VERSION "..\..\trunk\components\winTestMT\code\canApi\dbcFiles\canBus_10.dbc, created by Octave and generateRandomDbc.m on 21-Feb-2017"

NS_ :

BS_:

BU_: ECU

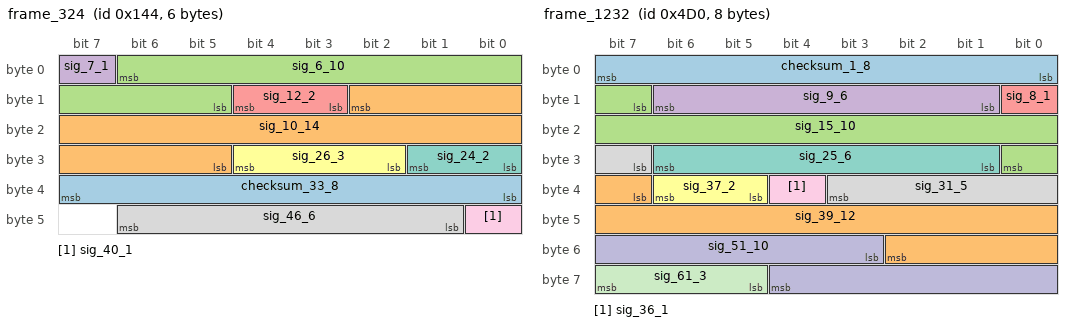
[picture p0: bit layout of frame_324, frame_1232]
BO_ 324 frame_324: 6 Vector__XXX
  SG_ checksum_33_8 : 32|8@1+ (1.0,0.0) [0.0|255.0] "" ECU
  SG_ sig_10_14 : 10|14@0+ (1.0000000000000009E-9,3.162277660168379E-6) [3.162277660168379E-6|1.954427766016839E-5] "km/h" ECU
  SG_ sig_6_10 : 6|10@0- (1.0,0.0) [-512.0|510.0] "" ECU
  SG_ sig_7_1 : 7|1@0+ (1.0,0.0) [0.0|1.0] "" ECU
  SG_ sig_12_2 : 12|2@0+ (1.0,0.0) [0.0|3.0] "" ECU
  SG_ sig_26_3 : 26|3@1+ (1.0,0.0) [0.0|6.0] "" ECU
  SG_ sig_24_2 : 24|2@1+ (1.0,0.0) [0.0|3.0] "" ECU
  SG_ sig_46_6 : 46|6@0+ (1.0000000000000006E-6,0.0) [0.0|6.200000000000004E-5] "kWh" ECU
  SG_ sig_40_1 : 40|1@1+ (1.0,0.0) [0.0|1.0] "" ECU

BO_ 1232 frame_1232: 8 Vector__XXX
  SG_ checksum_1_8 : 0|8@1+ (1.0,0.0) [0.0|255.0] "" ECU
  SG_ sig_39_12 : 39|12@1+ (1.0000000000000008E-8,-3.1622776601683795E-5) [-3.1622776601683795E-5|9.317223398316236E-6] "m/s^2" ECU
  SG_ sig_15_10 : 15|10@1+ (0.010000000000000002,3.1622776601683795) [3.1622776601683795|13.382277660168382] "V" ECU
  SG_ sig_9_6 : 9|6@1- (1.0000000000000005E-4,-0.0031622776601683794) [-0.006362277660168381|-1.6227766016837803E-4] "W" ECU
  SG_ sig_8_1 : 8|1@1+ (1.0,0.0) [0.0|1.0] "" ECU
  SG_ sig_37_2 : 37|2@1+ (1.0,0.0) [0.0|3.0] "" ECU
  SG_ sig_25_6 : 25|6@1- (1000.0,0.0) [-32000.0|30000.0] "s" ECU
  SG_ sig_31_5 : 31|5@1+ (1000.0,-31622.776601683792) [-31622.776601683792|-1622.7766016837923] "V" ECU
  SG_ sig_36_1 : 36|1@1+ (1.0,0.0) [0.0|1.0] "" ECU
  SG_ sig_51_10 : 51|10@1- (0.0010000000000000002,0.31622776601683794) [-0.19577223398316218|0.826227766016838] "A" ECU
  SG_ sig_61_3 : 61|3@1+ (1.0,0.0) [0.0|6.0] "" ECU

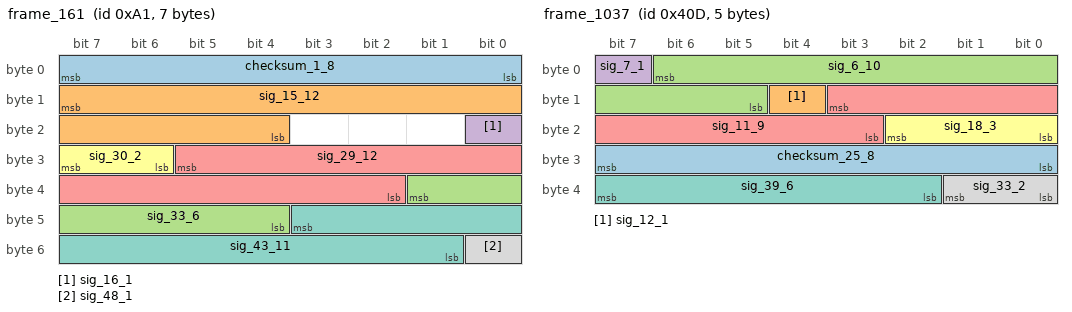
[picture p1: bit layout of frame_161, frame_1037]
BO_ 161 frame_161: 7 Vector__XXX
  SG_ checksum_1_8 : 0|8@1+ (1.0,0.0) [0.0|255.0] "" ECU
  SG_ sig_15_12 : 15|12@0- (0.010000000000000002,-31.622776601683793) [-52.1027766016838|-11.162776601683788] "km/h" ECU
  SG_ sig_33_6 : 33|6@0+ (0.1,0.0) [0.0|6.2] "km/h" ECU
  SG_ sig_16_1 : 16|1@1+ (1.0,0.0) [0.0|1.0] "" ECU
  SG_ sig_29_12 : 29|12@0- (1.0,0.0) [-2048.0|2046.0] "" ECU
  SG_ sig_30_2 : 30|2@1+ (1.0,0.0) [0.0|3.0] "" ECU
  SG_ sig_43_11 : 43|11@0+ (1.0000000000000008E-8,0.0) [0.0|2.0460000000000018E-5] "kWh" ECU
  SG_ sig_48_1 : 48|1@0+ (1.0,0.0) [0.0|1.0] "" ECU

BO_ 1037 frame_1037: 5 Vector__XXX
  SG_ checksum_25_8 : 31|8@0+ (1.0,0.0) [0.0|255.0] "" ECU
  SG_ sig_12_1 : 12|1@0+ (1.0,0.0) [0.0|1.0] "" ECU
  SG_ sig_6_10 : 6|10@0- (1.0,0.0) [-512.0|510.0] "" ECU
  SG_ sig_7_1 : 7|1@0+ (1.0,0.0) [0.0|1.0] "" ECU
  SG_ sig_11_9 : 11|9@0- (0.0010000000000000002,0.31622776601683794) [0.06022776601683788|0.570227766016838] "kWh" ECU
  SG_ sig_18_3 : 18|3@0- (1.0,0.0) [-4.0|2.0] "" ECU
  SG_ sig_39_6 : 39|6@0- (1.0,0.0) [-32.0|30.0] "" ECU
  SG_ sig_33_2 : 33|2@0- (1.0,0.0) [-2.0|1.0] "" ECU

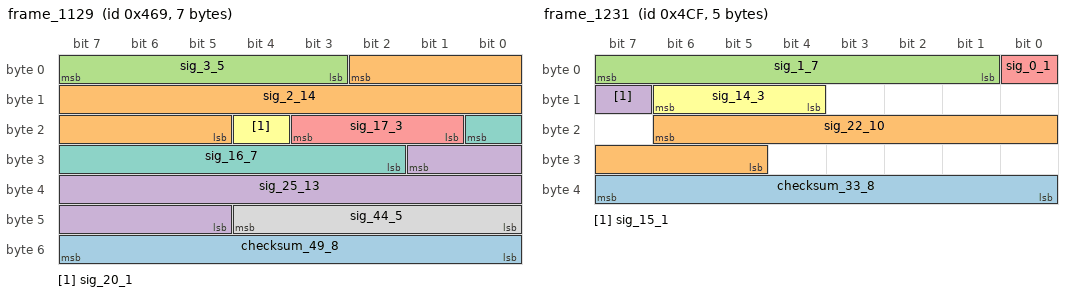
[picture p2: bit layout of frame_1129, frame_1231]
BO_ 1129 frame_1129: 7 Vector__XXX
  SG_ checksum_49_8 : 48|8@1+ (1.0,0.0) [0.0|255.0] "" ECU
  SG_ sig_2_14 : 2|14@0- (1.0000000000000009E-9,0.0) [-8.192000000000007E-6|8.190000000000008E-6] "kWh" ECU
  SG_ sig_3_5 : 3|5@1+ (1.0,0.0) [0.0|30.0] "" ECU
  SG_ sig_25_13 : 25|13@0+ (1.0,0.0) [0.0|8190.0] "" ECU
  SG_ sig_17_3 : 17|3@1+ (1.0,0.0) [0.0|6.0] "" ECU
  SG_ sig_20_1 : 20|1@0+ (1.0,0.0) [0.0|1.0] "" ECU
  SG_ sig_16_7 : 16|7@0- (1000.0,31622.776601683792) [-32377.223398316208|93622.77660168378] "s" ECU
  SG_ sig_44_5 : 44|5@0+ (1.0000000000000005E-4,0.0) [0.0|0.0030000000000000014] "V" ECU

BO_ 1231 frame_1231: 5 Vector__XXX
  SG_ checksum_33_8 : 32|8@1+ (1.0,0.0) [0.0|255.0] "" ECU
  SG_ sig_22_10 : 22|10@0+ (1.0000000000000007E-7,-3.1622776601683795E-5) [-3.1622776601683795E-5|7.057722339831628E-5] "s" ECU
  SG_ sig_1_7 : 1|7@1+ (100.0,3162.2776601683795) [3162.2776601683795|15762.27766016838] "A" ECU
  SG_ sig_15_1 : 15|1@0+ (1.0,0.0) [0.0|1.0] "" ECU
  SG_ sig_0_1 : 0|1@1+ (1.0,0.0) [0.0|1.0] "" ECU
  SG_ sig_14_3 : 14|3@0- (1.0,0.0) [-4.0|2.0] "" ECU

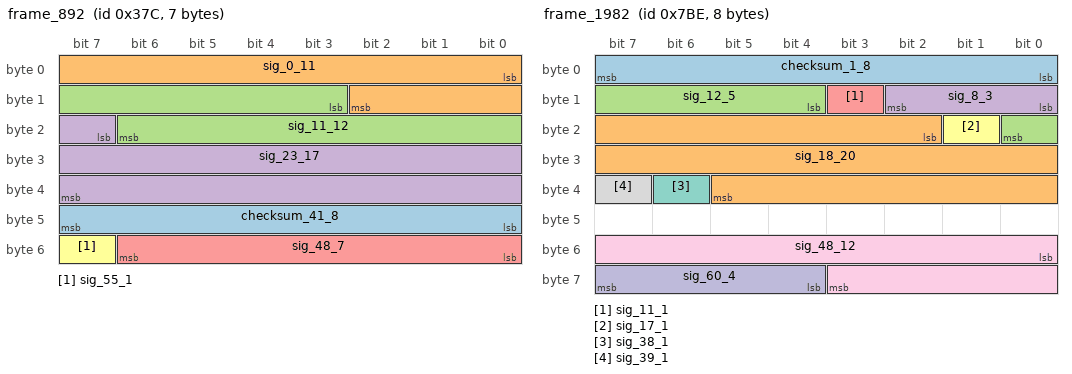
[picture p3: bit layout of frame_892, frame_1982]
BO_ 892 frame_892: 7 Vector__XXX
  SG_ checksum_41_8 : 40|8@1+ (1.0,0.0) [0.0|255.0] "" ECU
  SG_ sig_0_11 : 0|11@1- (0.1,-31.622776601683793) [-134.0227766016838|70.5772233983162] "s" ECU
  SG_ sig_11_12 : 11|12@1+ (1.0000000000000005E-4,0.0) [0.0|0.4094000000000002] "W" ECU
  SG_ sig_23_17 : 23|17@1- (0.1,-3162.2776601683795) [-9715.87766016838|3391.122339831621] "A" ECU
  SG_ sig_48_7 : 48|7@1+ (1.0000000000000006E-6,3.1622776601683795E-5) [3.1622776601683795E-5|1.5762277660168387E-4] "V" ECU
  SG_ sig_55_1 : 55|1@1+ (1.0,0.0) [0.0|1.0] "" ECU

BO_ 612 frame_612: 5 ECU
  SG_ checksum_1_8 : 7|8@0+ (1.0,0.0) [0.0|255.0] "" Vector__XXX
  SG_ sig_16_16 : 16|16@0- (1.0000000000000005E-4,3.1622776601683795) [-0.11452233983162197|6.438877660168381] "m/s^2" Vector__XXX
  SG_ sig_15_9 : 15|9@0+ (1.0000000000000007E-7,-3.1622776601683795E-5) [-3.1622776601683795E-5|1.9377223398316245E-5] "kWh" Vector__XXX
  SG_ sig_22_6 : 22|6@0+ (0.0010000000000000002,-0.03162277660168379) [-0.03162277660168379|0.030377223398316222] "A" Vector__XXX

BO_ 1982 frame_1982: 8 Vector__XXX
  SG_ checksum_1_8 : 0|8@1+ (1.0,0.0) [0.0|255.0] "" ECU
  SG_ sig_18_20 : 18|20@1+ (1.000000000000001E-11,3.162277660168379E-6) [3.162277660168379E-6|1.364801766016839E-5] "A" ECU
  SG_ sig_12_5 : 12|5@1+ (1.0000000000000007E-7,0.0) [0.0|3.000000000000002E-6] "kWh" ECU
  SG_ sig_8_3 : 8|3@1+ (1.0,0.0) [0.0|6.0] "" ECU
  SG_ sig_11_1 : 11|1@1+ (1.0,0.0) [0.0|1.0] "" ECU
  SG_ sig_17_1 : 17|1@1+ (1.0,0.0) [0.0|1.0] "" ECU
  SG_ sig_38_1 : 38|1@1+ (1.0,0.0) [0.0|1.0] "" ECU
  SG_ sig_39_1 : 39|1@1+ (1.0,0.0) [0.0|1.0] "" ECU
  SG_ sig_48_12 : 48|12@1- (1.0000000000000007E-7,0.0) [-2.0480000000000015E-4|2.0460000000000015E-4] "kWh" ECU
  SG_ sig_60_4 : 60|4@1- (10000.0,-31622.776601683792) [-111622.77660168378|28377.223398316208] "A" ECU

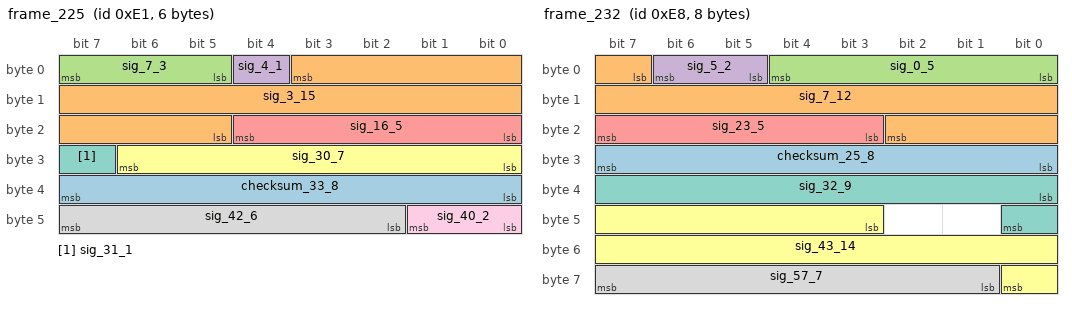
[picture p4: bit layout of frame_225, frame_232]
BO_ 225 frame_225: 6 Vector__XXX
  SG_ checksum_33_8 : 32|8@1+ (1.0,0.0) [0.0|255.0] "" ECU
  SG_ sig_3_15 : 3|15@0- (1.0,0.0) [-16384.0|16382.0] "" ECU
  SG_ sig_7_3 : 7|3@0- (1.0,0.0) [-4.0|2.0] "" ECU
  SG_ sig_4_1 : 4|1@0+ (1.0,0.0) [0.0|1.0] "" ECU
  SG_ sig_16_5 : 16|5@1+ (1.0000000000000006E-6,3.1622776601683795E-5) [3.1622776601683795E-5|6.162277660168381E-5] "m/s^2" ECU
  SG_ sig_30_7 : 30|7@0- (1.0,0.0) [-64.0|62.0] "" ECU
  SG_ sig_31_1 : 31|1@1+ (1.0,0.0) [0.0|1.0] "" ECU
  SG_ sig_42_6 : 42|6@1- (0.1,-3.1622776601683795) [-6.362277660168379|-0.16227766016837952] "kWh" ECU
  SG_ sig_40_2 : 40|2@1+ (1.0,0.0) [0.0|3.0] "" ECU

BO_ 5 frame_5: 4 ECU
  SG_ checksum_17_8 : 23|8@0+ (1.0,0.0) [0.0|255.0] "" Vector__XXX
  SG_ sig_0_13 : 0|13@1- (1.0000000000000009E-9,0.0) [-4.096000000000004E-6|4.0940000000000035E-6] "s" Vector__XXX
  SG_ sig_31_8 : 31|8@0+ (1.0,0.0) [0.0|254.0] "" Vector__XXX

BO_ 232 frame_232: 8 Vector__XXX
  SG_ checksum_25_8 : 31|8@0+ (1.0,0.0) [0.0|255.0] "" ECU
  SG_ sig_7_12 : 7|12@1+ (1.0000000000000009E-9,0.0) [0.0|4.0940000000000035E-6] "A" ECU
  SG_ sig_0_5 : 0|5@1- (1.0000000000000006E-6,0.0) [-1.600000000000001E-5|1.4000000000000008E-5] "kWh" ECU
  SG_ sig_5_2 : 5|2@1+ (1.0,0.0) [0.0|3.0] "" ECU
  SG_ sig_23_5 : 23|5@0- (1.0,0.0) [-16.0|14.0] "" ECU
  SG_ sig_43_14 : 43|14@1- (1.0000000000000006E-5,0.03162277660168379) [-0.05029722339831626|0.11352277660168383] "km/h" ECU
  SG_ sig_32_9 : 32|9@1+ (100.0,0.0) [0.0|51000.0] "s" ECU
  SG_ sig_57_7 : 57|7@1+ (1000.0,31622.776601683792) [31622.776601683792|157622.77660168378] "W" ECU

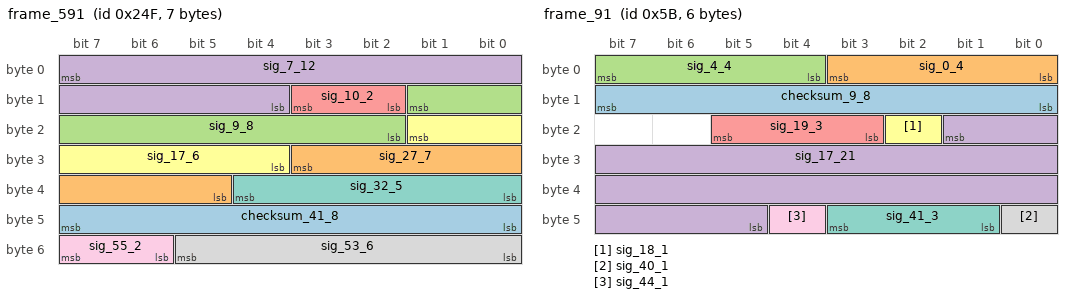
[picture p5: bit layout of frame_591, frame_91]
BO_ 591 frame_591: 7 Vector__XXX
  SG_ checksum_41_8 : 40|8@1+ (1.0,0.0) [0.0|255.0] "" ECU
  SG_ sig_27_7 : 27|7@0+ (0.0010000000000000002,0.03162277660168379) [0.03162277660168379|0.15762277660168383] "km/h" ECU
  SG_ sig_9_8 : 9|8@0+ (100.0,3162.2776601683795) [3162.2776601683795|28562.27766016838] "kWh" ECU
  SG_ sig_7_12 : 7|12@0- (1.0000000000000009E-9,3.162277660168379E-6) [1.1142776601683774E-6|5.208277660168381E-6] "A" ECU
  SG_ sig_10_2 : 10|2@1+ (1.0,0.0) [0.0|3.0] "" ECU
  SG_ sig_17_6 : 17|6@0+ (10.0,-316.22776601683796) [-316.22776601683796|303.77223398316204] "A" ECU
  SG_ sig_32_5 : 32|5@1- (1000.0,0.0) [-16000.0|14000.0] "A" ECU
  SG_ sig_53_6 : 53|6@0- (1.0,0.0) [-32.0|30.0] "" ECU
  SG_ sig_55_2 : 55|2@0- (1.0,0.0) [-2.0|1.0] "" ECU

BO_ 91 frame_91: 6 Vector__XXX
  SG_ checksum_9_8 : 8|8@1+ (1.0,0.0) [0.0|255.0] "" ECU
  SG_ sig_0_4 : 0|4@1- (1.0000000000000005E-4,-3.1622776601683794E-4) [-0.0011162277660168383|2.8377223398316233E-4] "V" ECU
  SG_ sig_4_4 : 4|4@1- (1.0,0.0) [-8.0|6.0] "" ECU
  SG_ sig_17_21 : 17|21@0+ (1.000000000000001E-11,-3.162277660168379E-6) [-3.162277660168379E-6|1.7809222339831644E-5] "kWh" ECU
  SG_ sig_19_3 : 19|3@1- (1.0,0.0) [-4.0|2.0] "" ECU
  SG_ sig_18_1 : 18|1@1+ (1.0,0.0) [0.0|1.0] "" ECU
  SG_ sig_41_3 : 41|3@1+ (1.0,0.0) [0.0|6.0] "" ECU
  SG_ sig_40_1 : 40|1@1+ (1.0,0.0) [0.0|1.0] "" ECU
  SG_ sig_44_1 : 44|1@1+ (1.0,0.0) [0.0|1.0] "" ECU

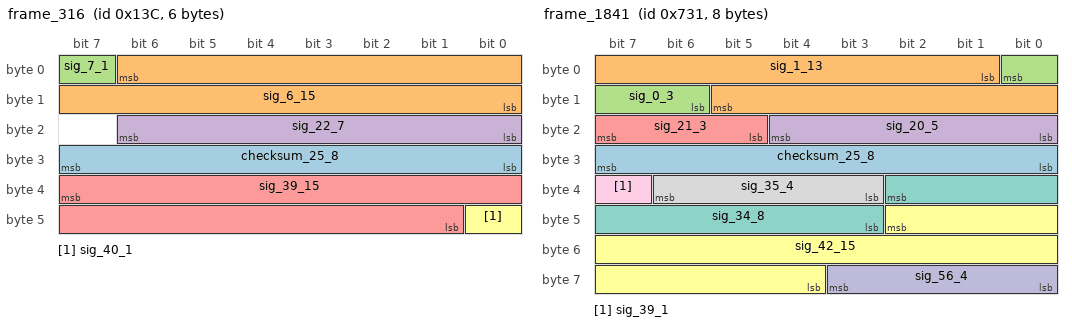
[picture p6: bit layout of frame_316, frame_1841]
BO_ 316 frame_316: 6 Vector__XXX
  SG_ checksum_25_8 : 31|8@0+ (1.0,0.0) [0.0|255.0] "" ECU
  SG_ sig_6_15 : 6|15@0+ (1.0000000000000008E-8,0.0) [0.0|3.276600000000003E-4] "m/s^2" ECU
  SG_ sig_7_1 : 7|1@0+ (1.0,0.0) [0.0|1.0] "" ECU
  SG_ sig_22_7 : 22|7@0- (1000.0,31622.776601683792) [-32377.223398316208|93622.77660168378] "W" ECU
  SG_ sig_39_15 : 39|15@0+ (1.0000000000000009E-9,3.1622776601683795E-5) [3.1622776601683795E-5|6.438877660168383E-5] "s" ECU
  SG_ sig_40_1 : 40|1@0+ (1.0,0.0) [0.0|1.0] "" ECU

BO_ 1841 frame_1841: 8 Vector__XXX
  SG_ checksum_25_8 : 24|8@1+ (1.0,0.0) [0.0|255.0] "" ECU
  SG_ sig_1_13 : 1|13@1+ (1.0000000000000008E-8,-3.1622776601683795E-5) [-3.1622776601683795E-5|5.027722339831627E-5] "A" ECU
  SG_ sig_0_3 : 0|3@0- (1.0,0.0) [-4.0|2.0] "" ECU
  SG_ sig_20_5 : 20|5@0- (1.0,0.0) [-16.0|14.0] "" ECU
  SG_ sig_21_3 : 21|3@1- (1.0,0.0) [-4.0|2.0] "" ECU
  SG_ sig_42_15 : 42|15@0+ (1.0,0.0) [0.0|32766.0] "" ECU
  SG_ sig_34_8 : 34|8@0- (1.0,0.0) [-128.0|126.0] "" ECU
  SG_ sig_35_4 : 35|4@1- (10000.0,-31622.776601683792) [-111622.77660168378|28377.223398316208] "s" ECU
  SG_ sig_39_1 : 39|1@0+ (1.0,0.0) [0.0|1.0] "" ECU
  SG_ sig_56_4 : 56|4@1+ (100.0,316.22776601683796) [316.22776601683796|1716.227766016838] "A" ECU

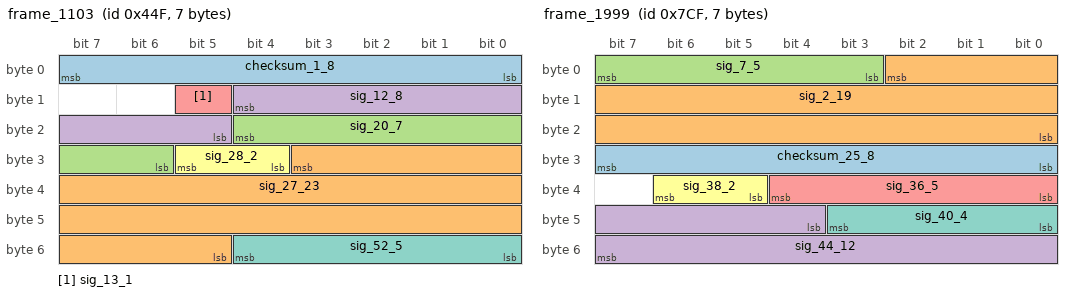
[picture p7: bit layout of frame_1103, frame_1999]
BO_ 1103 frame_1103: 7 Vector__XXX
  SG_ checksum_1_8 : 0|8@1+ (1.0,0.0) [0.0|255.0] "" ECU
  SG_ sig_27_23 : 27|23@0- (1.0000000000000014E-12,-3.162277660168379E-6) [-7.356581660168385E-6|1.032024339831627E-6] "km/h" ECU
  SG_ sig_20_7 : 20|7@0- (0.0010000000000000002,0.03162277660168379) [-0.032377223398316224|0.0936227766016838] "kWh" ECU
  SG_ sig_12_8 : 12|8@0+ (1.0000000000000006E-5,-3.1622776601683794E-4) [-3.1622776601683794E-4|0.0022237722339831633] "m/s^2" ECU
  SG_ sig_13_1 : 13|1@1+ (1.0,0.0) [0.0|1.0] "" ECU
  SG_ sig_28_2 : 28|2@1+ (1.0,0.0) [0.0|3.0] "" ECU
  SG_ sig_52_5 : 52|5@0+ (0.1,-3.1622776601683795) [-3.1622776601683795|-0.16227766016837952] "W" ECU

BO_ 109 frame_109: 6 Vector__XXX
  SG_ checksum_33_8 : 32|8@1+ (1.0,0.0) [0.0|255.0] "" ECU
  SG_ sig_7_16 : 7|16@0- (0.010000000000000002,0.0) [-327.68000000000006|327.6600000000001] "kWh" ECU
  SG_ sig_17_5 : 17|5@0+ (1.0000000000000007E-7,0.0) [0.0|3.000000000000002E-6] "V" ECU
  SG_ sig_18_1 : 18|1@1+ (1.0,0.0) [0.0|1.0] "" ECU
  SG_ sig_47_5 : 47|5@0- (0.1,0.0) [-1.6|1.4000000000000001] "V" ECU
  SG_ sig_40_3 : 40|3@1- (1.0,0.0) [-4.0|2.0] "" ECU

BO_ 1999 frame_1999: 7 Vector__XXX
  SG_ checksum_25_8 : 24|8@1+ (1.0,0.0) [0.0|255.0] "" ECU
  SG_ sig_2_19 : 2|19@0+ (1.0,0.0) [0.0|524286.0] "" ECU
  SG_ sig_7_5 : 7|5@0- (1.0000000000000006E-6,3.1622776601683795E-5) [1.5622776601683786E-5|4.5622776601683804E-5] "km/h" ECU
  SG_ sig_44_12 : 44|12@1+ (0.0010000000000000002,0.0) [0.0|4.094000000000001] "V" ECU
  SG_ sig_36_5 : 36|5@0- (1000.0,0.0) [-16000.0|14000.0] "km/h" ECU
  SG_ sig_38_2 : 38|2@0+ (1.0,0.0) [0.0|3.0] "" ECU
  SG_ sig_40_4 : 40|4@1+ (0.1,-0.31622776601683794) [-0.31622776601683794|1.0837722339831621] "V" ECU

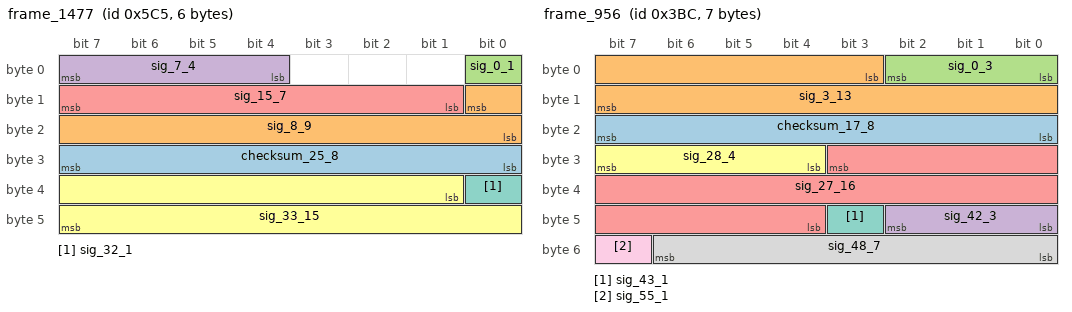
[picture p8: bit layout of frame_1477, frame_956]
BO_ 1477 frame_1477: 6 ECU
  SG_ checksum_25_8 : 24|8@1+ (1.0,0.0) [0.0|255.0] "" Vector__XXX
  SG_ sig_8_9 : 8|9@0- (1.0,0.0) [-256.0|254.0] "" Vector__XXX
  SG_ sig_0_1 : 0|1@1+ (1.0,0.0) [0.0|1.0] "" Vector__XXX
  SG_ sig_7_4 : 7|4@0+ (1.0000000000000005E-4,3.1622776601683794E-4) [3.1622776601683794E-4|0.0017162277660168386] "V" Vector__XXX
  SG_ sig_15_7 : 15|7@0- (0.0010000000000000002,0.03162277660168379) [-0.032377223398316224|0.0936227766016838] "km/h" Vector__XXX
  SG_ sig_33_15 : 33|15@1+ (0.1,3162.2776601683795) [3162.2776601683795|6438.87766016838] "km/h" Vector__XXX
  SG_ sig_32_1 : 32|1@1+ (1.0,0.0) [0.0|1.0] "" Vector__XXX

BO_ 956 frame_956: 7 Vector__XXX
  SG_ checksum_17_8 : 23|8@0+ (1.0,0.0) [0.0|255.0] "" ECU
  SG_ sig_3_13 : 3|13@1+ (1.0000000000000005E-4,0.0) [0.0|0.8190000000000004] "s" ECU
  SG_ sig_0_3 : 0|3@1- (1.0,0.0) [-4.0|2.0] "" ECU
  SG_ sig_42_3 : 42|3@0+ (1.0,0.0) [0.0|6.0] "" ECU
  SG_ sig_27_16 : 27|16@0- (1.0,0.0) [-32768.0|32766.0] "" ECU
  SG_ sig_28_4 : 28|4@1- (10.0,0.0) [-80.0|60.0] "W" ECU
  SG_ sig_43_1 : 43|1@0+ (1.0,0.0) [0.0|1.0] "" ECU
  SG_ sig_48_7 : 48|7@1+ (1.0000000000000006E-6,0.0) [0.0|1.2600000000000008E-4] "W" ECU
  SG_ sig_55_1 : 55|1@1+ (1.0,0.0) [0.0|1.0] "" ECU

BO_ 1604 frame_1604: 7 ECU
  SG_ checksum_9_8 : 8|8@1+ (1.0,0.0) [0.0|255.0] "" Vector__XXX
  SG_ sig_1_7 : 1|7@1+ (0.1,3.1622776601683795) [3.1622776601683795|15.762277660168381] "km/h" Vector__XXX
  SG_ sig_19_35 : 19|35@1+ (1.0000000000000008E-8,0.0) [0.0|343.5973836600003] "s" Vector__XXX
  SG_ sig_16_3 : 16|3@1- (1.0,0.0) [-4.0|2.0] "" Vector__XXX
  SG_ sig_54_2 : 54|2@1- (1.0,0.0) [-2.0|1.0] "" Vector__XXX

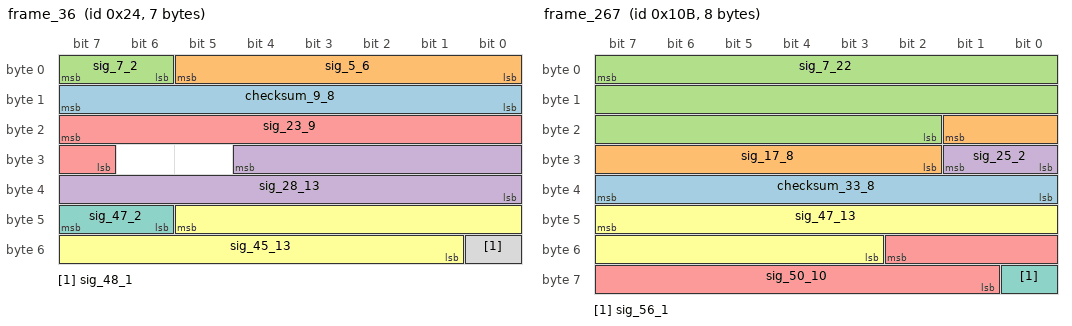
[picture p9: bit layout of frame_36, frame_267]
BO_ 36 frame_36: 7 ECU
  SG_ checksum_9_8 : 15|8@0+ (1.0,0.0) [0.0|255.0] "" Vector__XXX
  SG_ sig_5_6 : 5|6@0- (10.0,316.22776601683796) [-3.772233983162039|616.2277660168379] "V" Vector__XXX
  SG_ sig_7_2 : 7|2@0+ (1.0,0.0) [0.0|3.0] "" Vector__XXX
  SG_ sig_28_13 : 28|13@0- (0.0010000000000000002,0.0) [-4.096000000000001|4.094000000000001] "W" Vector__XXX
  SG_ sig_23_9 : 23|9@0+ (10.0,0.0) [0.0|5100.0] "A" Vector__XXX
  SG_ sig_45_13 : 45|13@0+ (1.0,0.0) [0.0|8190.0] "" Vector__XXX
  SG_ sig_47_2 : 47|2@0+ (1.0,0.0) [0.0|3.0] "" Vector__XXX
  SG_ sig_48_1 : 48|1@0+ (1.0,0.0) [0.0|1.0] "" Vector__XXX

BO_ 1847 frame_1847: 6 Vector__XXX
  SG_ checksum_1_8 : 0|8@1+ (1.0,0.0) [0.0|255.0] "" ECU
  SG_ sig_24_15 : 24|15@1+ (1.0,0.0) [0.0|32766.0] "" ECU
  SG_ sig_8_14 : 8|14@1- (1.0,0.0) [-8192.0|8190.0] "" ECU
  SG_ sig_22_2 : 22|2@1- (1.0,0.0) [-2.0|1.0] "" ECU
  SG_ sig_40_8 : 40|8@1+ (100.0,3162.2776601683795) [3162.2776601683795|28562.27766016838] "V" ECU
  SG_ sig_39_1 : 39|1@1+ (1.0,0.0) [0.0|1.0] "" ECU

BO_ 267 frame_267: 8 Vector__XXX
  SG_ checksum_33_8 : 39|8@0+ (1.0,0.0) [0.0|255.0] "" ECU
  SG_ sig_17_8 : 17|8@0+ (1.0,0.0) [0.0|254.0] "" ECU
  SG_ sig_7_22 : 7|22@0- (1.0000000000000011E-10,-3.1622776601683794E-4) [-5.259429660168382E-4|-1.065127660168377E-4] "km/h" ECU
  SG_ sig_25_2 : 25|2@0+ (1.0,0.0) [0.0|3.0] "" ECU
  SG_ sig_50_10 : 50|10@0- (100.0,31622.776601683792) [-19577.223398316208|82622.77660168378] "m/s^2" ECU
  SG_ sig_47_13 : 47|13@0- (1.0,0.0) [-4096.0|4094.0] "" ECU
  SG_ sig_56_1 : 56|1@0+ (1.0,0.0) [0.0|1.0] "" ECU

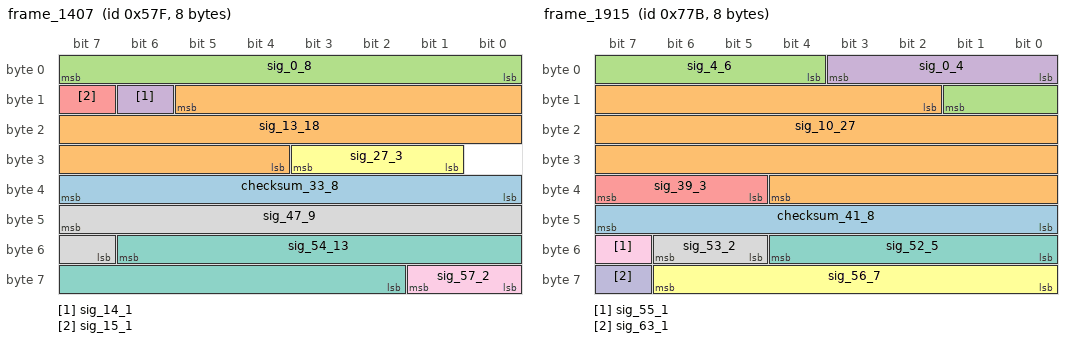
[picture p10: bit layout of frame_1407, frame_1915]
BO_ 1407 frame_1407: 8 Vector__XXX
  SG_ checksum_33_8 : 39|8@0+ (1.0,0.0) [0.0|255.0] "" ECU
  SG_ sig_13_18 : 13|18@0- (1.0,0.0) [-131072.0|131070.0] "" ECU
  SG_ sig_0_8 : 0|8@1+ (1.0000000000000006E-5,3.1622776601683794E-4) [3.1622776601683794E-4|0.0028562277660168396] "s" ECU
  SG_ sig_14_1 : 14|1@0+ (1.0,0.0) [0.0|1.0] "" ECU
  SG_ sig_15_1 : 15|1@0+ (1.0,0.0) [0.0|1.0] "" ECU
  SG_ sig_27_3 : 27|3@0- (1.0,0.0) [-4.0|2.0] "" ECU
  SG_ sig_54_13 : 54|13@0+ (1.0,0.0) [0.0|8190.0] "" ECU
  SG_ sig_47_9 : 47|9@0- (1.0,0.0) [-256.0|254.0] "s" ECU
  SG_ sig_57_2 : 57|2@0- (1.0,0.0) [-2.0|1.0] "" ECU

BO_ 1915 frame_1915: 8 Vector__XXX
  SG_ checksum_41_8 : 40|8@1+ (1.0,0.0) [0.0|255.0] "" ECU
  SG_ sig_10_27 : 10|27@1+ (1.0000000000000009E-9,-0.03162277660168379) [-0.03162277660168379|0.10259494939831633] "A" ECU
  SG_ sig_4_6 : 4|6@1+ (1.0,0.0) [0.0|62.0] "" ECU
  SG_ sig_0_4 : 0|4@1- (1.0000000000000006E-5,0.0) [-8.000000000000005E-5|6.0000000000000035E-5] "kWh" ECU
  SG_ sig_39_3 : 39|3@0+ (1.0,0.0) [0.0|6.0] "" ECU
  SG_ sig_56_7 : 56|7@1- (1.0,0.0) [-64.0|62.0] "" ECU
  SG_ sig_52_5 : 52|5@0+ (0.1,0.0) [0.0|3.0] "kWh" ECU
  SG_ sig_53_2 : 53|2@1- (1.0,0.0) [-2.0|1.0] "" ECU
  SG_ sig_55_1 : 55|1@0+ (1.0,0.0) [0.0|1.0] "" ECU
  SG_ sig_63_1 : 63|1@1+ (1.0,0.0) [0.0|1.0] "" ECU

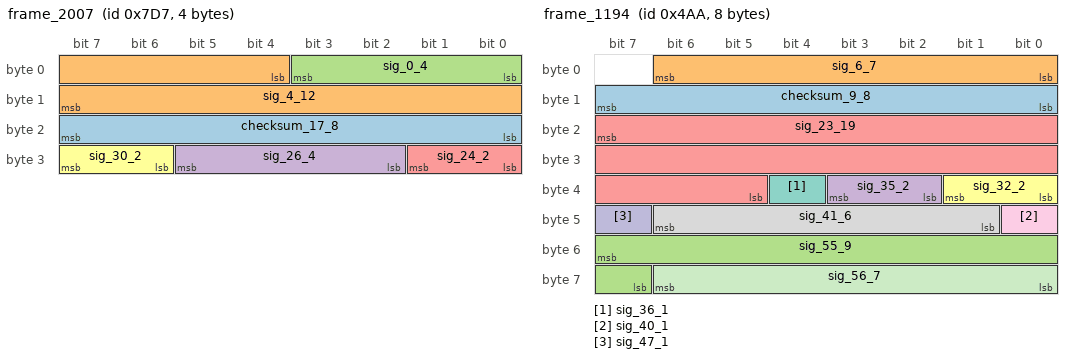
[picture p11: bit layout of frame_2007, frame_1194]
BO_ 2007 frame_2007: 4 Vector__XXX
  SG_ checksum_17_8 : 16|8@1+ (1.0,0.0) [0.0|255.0] "" ECU
  SG_ sig_4_12 : 4|12@1+ (1.0000000000000009E-9,0.0) [0.0|4.0940000000000035E-6] "V" ECU
  SG_ sig_0_4 : 0|4@1+ (1.0000000000000005E-4,-3.1622776601683794E-4) [-3.1622776601683794E-4|0.0010837722339831627] "A" ECU
  SG_ sig_26_4 : 26|4@1+ (0.0010000000000000002,0.0031622776601683794) [0.0031622776601683794|0.017162277660168382] "A" ECU
  SG_ sig_24_2 : 24|2@1+ (1.0,0.0) [0.0|3.0] "" ECU
  SG_ sig_30_2 : 30|2@1- (1.0,0.0) [-2.0|1.0] "" ECU

BO_ 1194 frame_1194: 8 Vector__XXX
  SG_ checksum_9_8 : 8|8@1+ (1.0,0.0) [0.0|255.0] "" ECU
  SG_ sig_6_7 : 6|7@0- (1.0,0.0) [-64.0|62.0] "" ECU
  SG_ sig_55_9 : 55|9@0+ (0.0010000000000000002,-0.31622776601683794) [-0.31622776601683794|0.19377223398316218] "W" ECU
  SG_ sig_35_2 : 35|2@0+ (1.0,0.0) [0.0|3.0] "" ECU
  SG_ sig_23_19 : 23|19@0+ (0.1,31622.776601683792) [31622.776601683792|84051.37660168379] "s" ECU
  SG_ sig_32_2 : 32|2@1- (1.0,0.0) [-2.0|1.0] "" ECU
  SG_ sig_36_1 : 36|1@1+ (1.0,0.0) [0.0|1.0] "" ECU
  SG_ sig_41_6 : 41|6@1+ (1.0,0.0) [0.0|62.0] "" ECU
  SG_ sig_40_1 : 40|1@1+ (1.0,0.0) [0.0|1.0] "" ECU
  SG_ sig_47_1 : 47|1@0+ (1.0,0.0) [0.0|1.0] "" ECU
  SG_ sig_56_7 : 56|7@1+ (1.0,0.0) [0.0|126.0] "" ECU

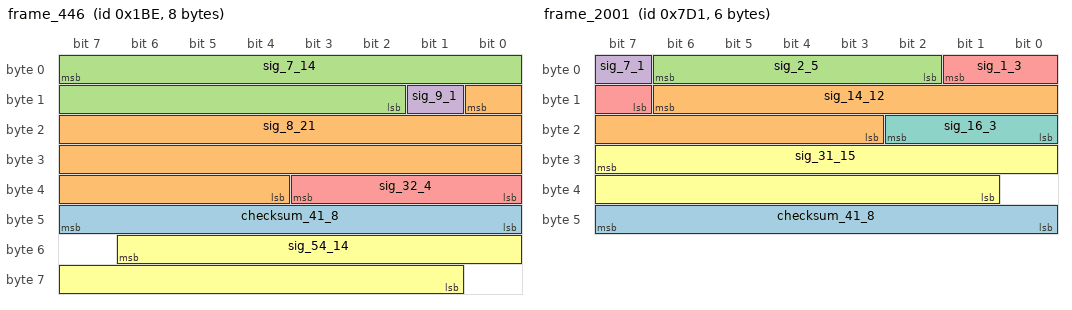
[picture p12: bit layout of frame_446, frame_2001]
BO_ 446 frame_446: 8 Vector__XXX
  SG_ checksum_41_8 : 40|8@1+ (1.0,0.0) [0.0|255.0] "" ECU
  SG_ sig_8_21 : 8|21@0- (1.0000000000000006E-6,0.0) [-1.0485760000000006|1.0485740000000006] "V" ECU
  SG_ sig_7_14 : 7|14@0- (1.0,0.0) [-8192.0|8190.0] "" ECU
  SG_ sig_9_1 : 9|1@0+ (1.0,0.0) [0.0|1.0] "" ECU
  SG_ sig_32_4 : 32|4@1- (0.0010000000000000002,-0.0031622776601683794) [-0.011162277660168382|0.0028377223398316225] "W" ECU
  SG_ sig_54_14 : 54|14@0+ (1.0,0.0) [0.0|16382.0] "" ECU

BO_ 1060 frame_1060: 3 Vector__XXX
  SG_ checksum_9_8 : 15|8@0+ (1.0,0.0) [0.0|255.0] "" ECU
  SG_ sig_1_7 : 1|7@1+ (1.0000000000000006E-5,3.1622776601683794E-4) [3.1622776601683794E-4|0.0015762277660168386] "V" ECU
  SG_ sig_0_1 : 0|1@1+ (1.0,0.0) [0.0|1.0] "" ECU
  SG_ sig_16_7 : 16|7@1+ (1.0,0.0) [0.0|126.0] "" ECU

BO_ 2001 frame_2001: 6 ECU
  SG_ checksum_41_8 : 47|8@0+ (1.0,0.0) [0.0|255.0] "" Vector__XXX
  SG_ sig_14_12 : 14|12@0- (1.0000000000000008E-8,3.1622776601683795E-5) [1.1142776601683778E-5|5.208277660168381E-5] "W" Vector__XXX
  SG_ sig_2_5 : 2|5@1+ (100.0,0.0) [0.0|3000.0] "A" Vector__XXX
  SG_ sig_7_1 : 7|1@0+ (1.0,0.0) [0.0|1.0] "" Vector__XXX
  SG_ sig_1_3 : 1|3@0+ (1.0,0.0) [0.0|6.0] "" Vector__XXX
  SG_ sig_31_15 : 31|15@0- (1.0,0.0) [-16384.0|16382.0] "" Vector__XXX
  SG_ sig_16_3 : 16|3@1- (1.0,0.0) [-4.0|2.0] "" Vector__XXX

BO_ 80 frame_80: 6 ECU
  SG_ checksum_1_8 : 7|8@0+ (1.0,0.0) [0.0|255.0] "" Vector__XXX
  SG_ sig_22_27 : 22|27@0- (1.0000000000000007E-7,0.0) [-6.710886400000005|6.710886200000005] "km/h" Vector__XXX
  SG_ sig_15_8 : 15|8@0+ (0.010000000000000002,-0.31622776601683794) [-0.31622776601683794|2.2237722339831625] "kWh" Vector__XXX
  SG_ sig_23_1 : 23|1@0+ (1.0,0.0) [0.0|1.0] "" Vector__XXX

BO_ 0 frame_0: 5 ECU
  SG_ checksum_1_8 : 7|8@0+ (1.0,0.0) [0.0|255.0] "" Vector__XXX
  SG_ sig_11_23 : 11|23@0+ (1.0000000000000014E-12,3.162277660168379E-6) [3.162277660168379E-6|1.155088366016839E-5] "m/s^2" Vector__XXX

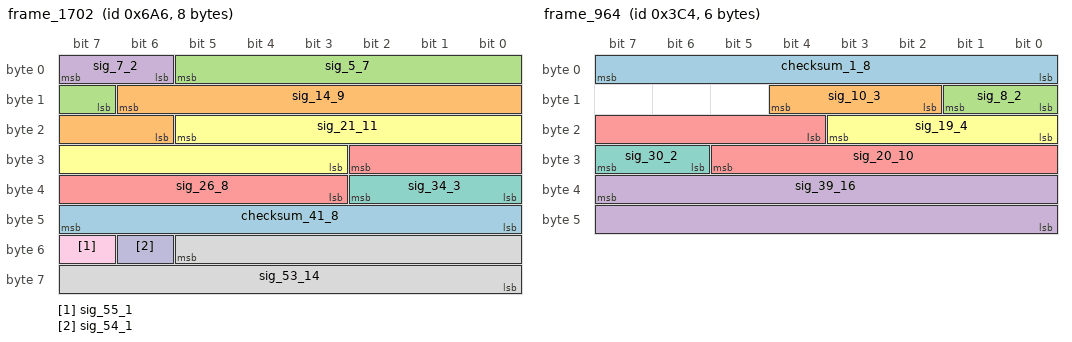
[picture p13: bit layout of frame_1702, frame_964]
BO_ 1702 frame_1702: 8 Vector__XXX
  SG_ checksum_41_8 : 47|8@0+ (1.0,0.0) [0.0|255.0] "" ECU
  SG_ sig_14_9 : 14|9@0- (1.0,0.0) [-256.0|254.0] "" ECU
  SG_ sig_5_7 : 5|7@0- (1.0,0.0) [-64.0|62.0] "" ECU
  SG_ sig_7_2 : 7|2@0- (1.0,0.0) [-2.0|1.0] "" ECU
  SG_ sig_26_8 : 26|8@0+ (0.0010000000000000002,-0.03162277660168379) [-0.03162277660168379|0.22237722339831628] "kWh" ECU
  SG_ sig_21_11 : 21|11@0- (1.0,0.0) [-1024.0|1022.0] "" ECU
  SG_ sig_34_3 : 34|3@0+ (1.0,0.0) [0.0|6.0] "" ECU
  SG_ sig_53_14 : 53|14@0+ (1.0000000000000007E-7,3.1622776601683794E-4) [3.1622776601683794E-4|0.0019544277660168393] "A" ECU
  SG_ sig_55_1 : 55|1@0+ (1.0,0.0) [0.0|1.0] "" ECU
  SG_ sig_54_1 : 54|1@0+ (1.0,0.0) [0.0|1.0] "" ECU

BO_ 1494 frame_1494: 4 ECU
  SG_ checksum_17_8 : 23|8@0+ (1.0,0.0) [0.0|255.0] "" Vector__XXX
  SG_ sig_5_11 : 5|11@1+ (1.0,0.0) [0.0|2046.0] "" Vector__XXX
  SG_ sig_1_4 : 1|4@1- (10000.0,31622.776601683792) [-48377.22339831621|91622.77660168378] "W" Vector__XXX
  SG_ sig_0_1 : 0|1@1+ (1.0,0.0) [0.0|1.0] "" Vector__XXX
  SG_ sig_31_3 : 31|3@0- (1.0,0.0) [-4.0|2.0] "" Vector__XXX

BO_ 964 frame_964: 6 Vector__XXX
  SG_ checksum_1_8 : 0|8@1+ (1.0,0.0) [0.0|255.0] "" ECU
  SG_ sig_10_3 : 10|3@1+ (1.0,0.0) [0.0|6.0] "" ECU
  SG_ sig_8_2 : 8|2@1- (1.0,0.0) [-2.0|1.0] "" ECU
  SG_ sig_39_16 : 39|16@0- (1.0,0.0) [-32768.0|32766.0] "W" ECU
  SG_ sig_20_10 : 20|10@1+ (1.0000000000000005E-4,-0.03162277660168379) [-0.03162277660168379|0.07057722339831625] "A" ECU
  SG_ sig_19_4 : 19|4@0+ (1.0,0.0) [0.0|14.0] "" ECU
  SG_ sig_30_2 : 30|2@1- (1.0,0.0) [-2.0|1.0] "" ECU

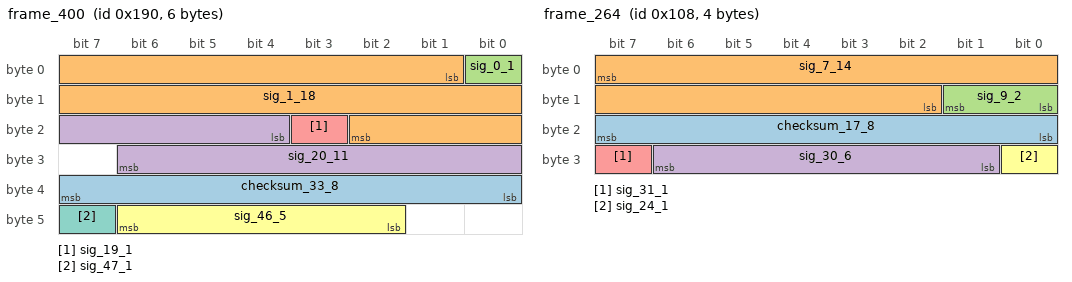
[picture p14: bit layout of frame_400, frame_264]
BO_ 400 frame_400: 6 Vector__XXX
  SG_ checksum_33_8 : 39|8@0+ (1.0,0.0) [0.0|255.0] "" ECU
  SG_ sig_1_18 : 1|18@1+ (1.0,0.0) [0.0|262142.0] "" ECU
  SG_ sig_0_1 : 0|1@1+ (1.0,0.0) [0.0|1.0] "" ECU
  SG_ sig_20_11 : 20|11@1- (1.0000000000000006E-6,0.0) [-0.0010240000000000006|0.0010220000000000006] "kWh" ECU
  SG_ sig_19_1 : 19|1@1+ (1.0,0.0) [0.0|1.0] "" ECU
  SG_ sig_46_5 : 46|5@0- (0.0010000000000000002,0.0) [-0.016000000000000004|0.014000000000000004] "W" ECU
  SG_ sig_47_1 : 47|1@0+ (1.0,0.0) [0.0|1.0] "" ECU

BO_ 264 frame_264: 4 Vector__XXX
  SG_ checksum_17_8 : 23|8@0+ (1.0,0.0) [0.0|255.0] "" ECU
  SG_ sig_7_14 : 7|14@0+ (0.010000000000000002,-31.622776601683793) [-31.622776601683793|132.19722339831623] "A" ECU
  SG_ sig_9_2 : 9|2@0+ (1.0,0.0) [0.0|3.0] "" ECU
  SG_ sig_30_6 : 30|6@0- (1.0,0.0) [-32.0|30.0] "" ECU
  SG_ sig_31_1 : 31|1@0+ (1.0,0.0) [0.0|1.0] "" ECU
  SG_ sig_24_1 : 24|1@1+ (1.0,0.0) [0.0|1.0] "" ECU

BO_ 479 frame_479: 6 Vector__XXX
  SG_ checksum_17_8 : 16|8@1+ (1.0,0.0) [0.0|255.0] "" ECU
  SG_ sig_0_16 : 0|16@1+ (0.1,3162.2776601683795) [3162.2776601683795|9715.67766016838] "A" ECU
  SG_ sig_30_12 : 30|12@1- (10.0,31622.776601683792) [11142.776601683792|52082.77660168379] "W" ECU
  SG_ sig_42_2 : 42|2@1+ (1.0,0.0) [0.0|3.0] "" ECU
  SG_ sig_47_1 : 47|1@1+ (1.0,0.0) [0.0|1.0] "" ECU

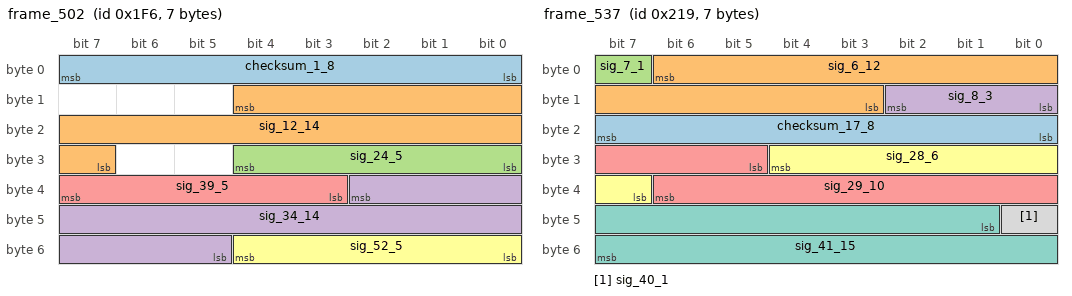
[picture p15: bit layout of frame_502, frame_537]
BO_ 502 frame_502: 7 Vector__XXX
  SG_ checksum_1_8 : 0|8@1+ (1.0,0.0) [0.0|255.0] "" ECU
  SG_ sig_12_14 : 12|14@0+ (1.0,0.0) [0.0|16382.0] "" ECU
  SG_ sig_24_5 : 24|5@1- (100.0,3162.2776601683795) [1562.2776601683795|4562.27766016838] "km/h" ECU
  SG_ sig_34_14 : 34|14@0+ (1.0000000000000008E-8,0.0) [0.0|1.6382000000000015E-4] "km/h" ECU
  SG_ sig_39_5 : 39|5@0- (1.0000000000000006E-5,-3.1622776601683794E-4) [-4.7622776601683803E-4|-1.7622776601683784E-4] "V" ECU
  SG_ sig_52_5 : 52|5@0- (0.1,3.1622776601683795) [1.5622776601683794|4.562277660168379] "V" ECU

BO_ 537 frame_537: 7 ECU
  SG_ checksum_17_8 : 16|8@1+ (1.0,0.0) [0.0|255.0] "" Vector__XXX
  SG_ sig_6_12 : 6|12@0- (1.0000000000000009E-9,0.0) [-2.048000000000002E-6|2.0460000000000017E-6] "m/s^2" Vector__XXX
  SG_ sig_7_1 : 7|1@0+ (1.0,0.0) [0.0|1.0] "" Vector__XXX
  SG_ sig_8_3 : 8|3@1+ (1.0,0.0) [0.0|6.0] "" Vector__XXX
  SG_ sig_29_10 : 29|10@1+ (1.0,0.0) [0.0|1022.0] "" Vector__XXX
  SG_ sig_28_6 : 28|6@0+ (1.0,0.0) [0.0|62.0] "" Vector__XXX
  SG_ sig_41_15 : 41|15@1- (0.0010000000000000002,0.0) [-16.384000000000004|16.382000000000005] "V" Vector__XXX
  SG_ sig_40_1 : 40|1@0+ (1.0,0.0) [0.0|1.0] "" Vector__XXX

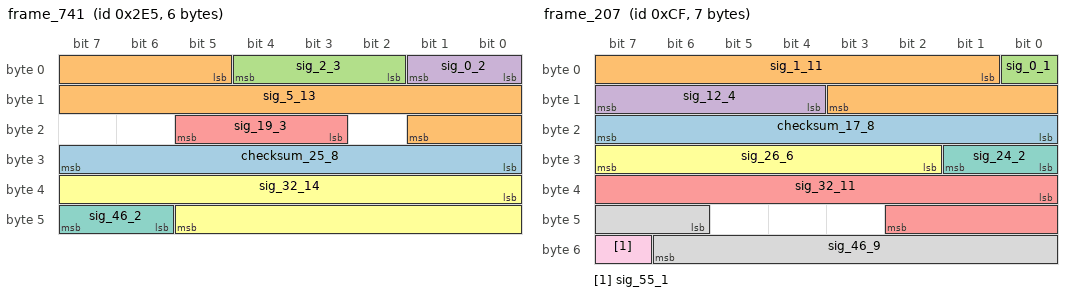
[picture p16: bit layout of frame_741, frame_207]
BO_ 741 frame_741: 6 ECU
  SG_ checksum_25_8 : 24|8@1+ (1.0,0.0) [0.0|255.0] "" Vector__XXX
  SG_ sig_5_13 : 5|13@1+ (1.0000000000000007E-7,3.1622776601683794E-4) [3.1622776601683794E-4|0.0011352277660168384] "W" Vector__XXX
  SG_ sig_2_3 : 2|3@1+ (1.0,0.0) [0.0|6.0] "" Vector__XXX
  SG_ sig_0_2 : 0|2@1- (1.0,0.0) [-2.0|1.0] "" Vector__XXX
  SG_ sig_19_3 : 19|3@1+ (1.0,0.0) [0.0|6.0] "" Vector__XXX
  SG_ sig_32_14 : 32|14@1- (1.0,0.0) [-8192.0|8190.0] "" Vector__XXX
  SG_ sig_46_2 : 46|2@1+ (1.0,0.0) [0.0|3.0] "" Vector__XXX

BO_ 1396 frame_1396: 2 ECU
  SG_ checksum_1_8 : 7|8@0+ (1.0,0.0) [0.0|255.0] "" Vector__XXX
  SG_ sig_8_8 : 8|8@1+ (1.0000000000000005E-4,-0.0031622776601683794) [-0.0031622776601683794|0.022237722339831633] "m/s^2" Vector__XXX

BO_ 207 frame_207: 7 ECU
  SG_ checksum_17_8 : 16|8@1+ (1.0,0.0) [0.0|255.0] "" Vector__XXX
  SG_ sig_1_11 : 1|11@1+ (0.1,31.622776601683793) [31.622776601683793|236.22277660168382] "km/h" Vector__XXX
  SG_ sig_0_1 : 0|1@1+ (1.0,0.0) [0.0|1.0] "" Vector__XXX
  SG_ sig_12_4 : 12|4@1- (0.0010000000000000002,0.0) [-0.008000000000000002|0.006000000000000002] "m/s^2" Vector__XXX
  SG_ sig_32_11 : 32|11@1- (1.0,0.0) [-1024.0|1022.0] "" Vector__XXX
  SG_ sig_26_6 : 26|6@1- (1.0,0.0) [-32.0|30.0] "" Vector__XXX
  SG_ sig_24_2 : 24|2@1+ (1.0,0.0) [0.0|3.0] "" Vector__XXX
  SG_ sig_46_9 : 46|9@1+ (1.0,0.0) [0.0|510.0] "" Vector__XXX
  SG_ sig_55_1 : 55|1@1+ (1.0,0.0) [0.0|1.0] "" Vector__XXX

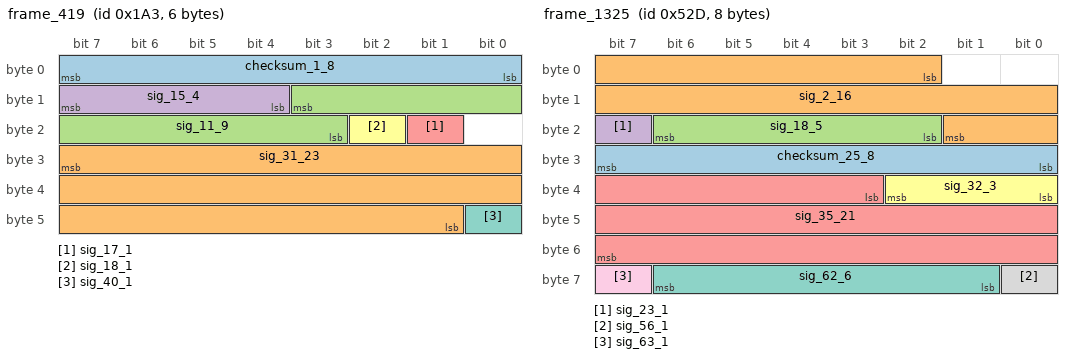
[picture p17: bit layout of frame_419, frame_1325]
BO_ 419 frame_419: 6 Vector__XXX
  SG_ checksum_1_8 : 7|8@0+ (1.0,0.0) [0.0|255.0] "" ECU
  SG_ sig_31_23 : 31|23@0+ (1.0000000000000008E-8,-0.03162277660168379) [-0.03162277660168379|0.052263283398316276] "A" ECU
  SG_ sig_11_9 : 11|9@0- (1.0000000000000008E-8,0.0) [-2.560000000000002E-6|2.5400000000000024E-6] "A" ECU
  SG_ sig_15_4 : 15|4@0+ (1000.0,-3162.2776601683795) [-3162.2776601683795|10837.72233983162] "km/h" ECU
  SG_ sig_17_1 : 17|1@0+ (1.0,0.0) [0.0|1.0] "" ECU
  SG_ sig_18_1 : 18|1@0+ (1.0,0.0) [0.0|1.0] "" ECU
  SG_ sig_40_1 : 40|1@0+ (1.0,0.0) [0.0|1.0] "" ECU

BO_ 1325 frame_1325: 8 Vector__XXX
  SG_ checksum_25_8 : 24|8@1+ (1.0,0.0) [0.0|255.0] "" ECU
  SG_ sig_2_16 : 2|16@1+ (1.0000000000000006E-5,0.0) [0.0|0.6553400000000004] "km/h" ECU
  SG_ sig_18_5 : 18|5@1+ (1.0,0.0) [0.0|30.0] "" ECU
  SG_ sig_23_1 : 23|1@1+ (1.0,0.0) [0.0|1.0] "" ECU
  SG_ sig_35_21 : 35|21@1- (0.0010000000000000002,-316.22776601683796) [-1364.8037660168382|732.3462339831624] "m/s^2" ECU
  SG_ sig_32_3 : 32|3@1- (1.0,0.0) [-4.0|2.0] "" ECU
  SG_ sig_62_6 : 62|6@0- (0.0010000000000000002,-0.03162277660168379) [-0.0636227766016838|-0.0016227766016837855] "A" ECU
  SG_ sig_56_1 : 56|1@1+ (1.0,0.0) [0.0|1.0] "" ECU
  SG_ sig_63_1 : 63|1@1+ (1.0,0.0) [0.0|1.0] "" ECU

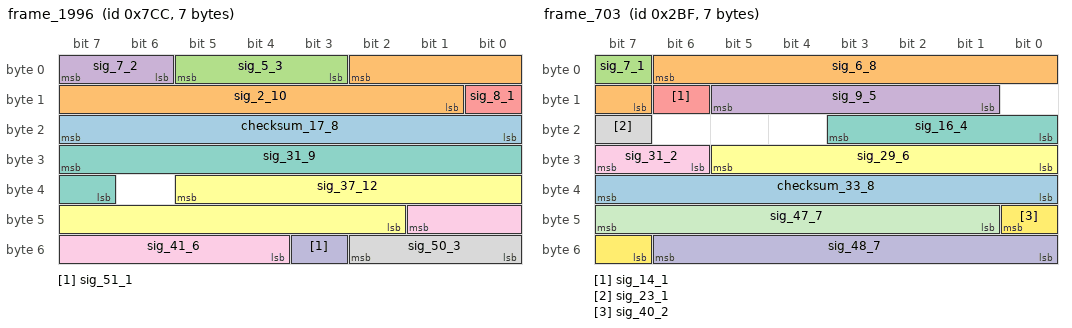
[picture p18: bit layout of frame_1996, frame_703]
BO_ 1996 frame_1996: 7 ECU
  SG_ checksum_17_8 : 23|8@0+ (1.0,0.0) [0.0|255.0] "" Vector__XXX
  SG_ sig_2_10 : 2|10@0- (1.0,0.0) [-512.0|510.0] "" Vector__XXX
  SG_ sig_5_3 : 5|3@0- (1.0,0.0) [-4.0|2.0] "" Vector__XXX
  SG_ sig_7_2 : 7|2@0- (1.0,0.0) [-2.0|1.0] "" Vector__XXX
  SG_ sig_8_1 : 8|1@0+ (1.0,0.0) [0.0|1.0] "" Vector__XXX
  SG_ sig_37_12 : 37|12@0- (1.0,0.0) [-2048.0|2046.0] "" Vector__XXX
  SG_ sig_31_9 : 31|9@0- (1.0,0.0) [-256.0|254.0] "" Vector__XXX
  SG_ sig_50_3 : 50|3@0- (1.0,0.0) [-4.0|2.0] "" Vector__XXX
  SG_ sig_41_6 : 41|6@0+ (1.0,31.622776601683793) [31.622776601683793|93.6227766016838] "V" Vector__XXX
  SG_ sig_51_1 : 51|1@0+ (1.0,0.0) [0.0|1.0] "" Vector__XXX

BO_ 1505 frame_1505: 6 ECU
  SG_ checksum_17_8 : 16|8@1+ (1.0,0.0) [0.0|255.0] "" Vector__XXX
  SG_ sig_3_13 : 3|13@1+ (1.0000000000000008E-8,-3.1622776601683795E-5) [-3.1622776601683795E-5|5.027722339831627E-5] "s" Vector__XXX
  SG_ sig_2_3 : 2|3@0+ (1.0,0.0) [0.0|6.0] "" Vector__XXX
  SG_ sig_27_9 : 27|9@1+ (0.1,31.622776601683793) [31.622776601683793|82.6227766016838] "V" Vector__XXX
  SG_ sig_24_3 : 24|3@1- (1.0,0.0) [-4.0|2.0] "" Vector__XXX
  SG_ sig_36_12 : 36|12@1+ (1.0000000000000008E-8,3.1622776601683795E-5) [3.1622776601683795E-5|7.256277660168383E-5] "m/s^2" Vector__XXX

BO_ 393 frame_393: 6 Vector__XXX
  SG_ checksum_25_8 : 31|8@0+ (1.0,0.0) [0.0|255.0] "" ECU
  SG_ sig_9_12 : 9|12@1- (1.0,0.0) [-2048.0|2046.0] "" ECU
  SG_ sig_7_8 : 7|8@0- (0.1,3.1622776601683795) [-9.63772233983162|15.762277660168381] "s" ECU
  SG_ sig_8_1 : 8|1@1+ (1.0,0.0) [0.0|1.0] "" ECU
  SG_ sig_22_2 : 22|2@0- (1.0,0.0) [-2.0|1.0] "" ECU
  SG_ sig_47_1 : 47|1@1+ (1.0,0.0) [0.0|1.0] "" ECU

BO_ 703 frame_703: 7 Vector__XXX
  SG_ checksum_33_8 : 32|8@1+ (1.0,0.0) [0.0|255.0] "" ECU
  SG_ sig_6_8 : 6|8@0- (1.0000000000000005E-4,-0.0031622776601683794) [-0.015962277660168386|0.009437722339831625] "s" ECU
  SG_ sig_7_1 : 7|1@0+ (1.0,0.0) [0.0|1.0] "" ECU
  SG_ sig_9_5 : 9|5@1- (1.0000000000000007E-7,3.162277660168379E-6) [1.562277660168378E-6|4.56227766016838E-6] "kWh" ECU
  SG_ sig_14_1 : 14|1@0+ (1.0,0.0) [0.0|1.0] "" ECU
  SG_ sig_29_6 : 29|6@0+ (1.0,0.0) [0.0|62.0] "" ECU
  SG_ sig_16_4 : 16|4@1+ (1.0000000000000006E-6,3.162277660168379E-6) [3.162277660168379E-6|1.7162277660168386E-5] "m/s^2" ECU
  SG_ sig_23_1 : 23|1@1+ (1.0,0.0) [0.0|1.0] "" ECU
  SG_ sig_31_2 : 31|2@0+ (1.0,0.0) [0.0|3.0] "" ECU
  SG_ sig_48_7 : 48|7@1+ (1.0000000000000005E-4,0.0) [0.0|0.012600000000000005] "kWh" ECU
  SG_ sig_47_7 : 47|7@0+ (1.0,0.0) [0.0|126.0] "" ECU
  SG_ sig_40_2 : 40|2@0- (1.0,0.0) [-2.0|1.0] "" ECU

BO_ 48 frame_48: 8 Vector__XXX
  SG_ checksum_33_8 : 39|8@0+ (1.0,0.0) [0.0|255.0] "" ECU
  SG_ sig_7_10 : 7|10@0- (10.0,0.0) [-5120.0|5100.0] "V" ECU
  SG_ sig_30_7 : 30|7@0- (1.0,0.0) [-64.0|62.0] "" ECU
  SG_ sig_13_12 : 13|12@0- (1.0,0.0) [-2048.0|2046.0] "" ECU
  SG_ sig_52_13 : 52|13@0+ (1.0000000000000005E-4,0.31622776601683794) [0.31622776601683794|1.1352277660168384] "m/s^2" ECU
  SG_ sig_47_11 : 47|11@0- (100.0,0.0) [-102400.0|102200.0] "s" ECU

BO_ 26 frame_26: 7 ECU
  SG_ checksum_9_8 : 15|8@0+ (1.0,0.0) [0.0|255.0] "" Vector__XXX
  SG_ sig_0_8 : 0|8@1- (1.0000000000000007E-7,0.0) [-1.280000000000001E-5|1.260000000000001E-5] "A" Vector__XXX
  SG_ sig_31_28 : 31|28@0+ (1.0000000000000005E-4,3162.2776601683795) [3162.2776601683795|30005.823060168394] "s" Vector__XXX
  SG_ sig_17_7 : 17|7@1- (1.0,0.0) [-64.0|62.0] "" Vector__XXX
  SG_ sig_16_1 : 16|1@0+ (1.0,0.0) [0.0|1.0] "" Vector__XXX
  SG_ sig_48_1 : 48|1@0+ (1.0,0.0) [0.0|1.0] "" Vector__XXX

BO_ 515 frame_515: 4 ECU
  SG_ checksum_9_8 : 15|8@0+ (1.0,0.0) [0.0|255.0] "" Vector__XXX
  SG_ sig_6_7 : 6|7@0+ (1.0,0.0) [0.0|126.0] "" Vector__XXX
  SG_ sig_7_1 : 7|1@1+ (1.0,0.0) [0.0|1.0] "" Vector__XXX
  SG_ sig_22_14 : 22|14@0+ (1.0000000000000009E-9,3.162277660168379E-6) [3.162277660168379E-6|1.954427766016839E-5] "m/s^2" Vector__XXX
  SG_ sig_23_2 : 23|2@1+ (1.0,0.0) [0.0|3.0] "" Vector__XXX

BO_ 1570 frame_1570: 7 Vector__XXX
  SG_ checksum_33_8 : 32|8@1+ (1.0,0.0) [0.0|255.0] "" ECU
  SG_ sig_14_16 : 14|16@1- (1.0000000000000006E-5,0.31622776601683794) [-0.011452233983162252|0.6438877660168381] "kWh" ECU
  SG_ sig_0_8 : 0|8@1- (1.0,0.0) [-128.0|126.0] "" ECU
  SG_ sig_8_6 : 8|6@1+ (0.010000000000000002,0.31622776601683794) [0.31622776601683794|0.9362277660168381] "s" ECU
  SG_ sig_42_14 : 42|14@1+ (1.0000000000000006E-6,-0.0031622776601683794) [-0.0031622776601683794|0.013219722339831631] "A" ECU
  SG_ sig_40_2 : 40|2@1- (1.0,0.0) [-2.0|1.0] "" ECU

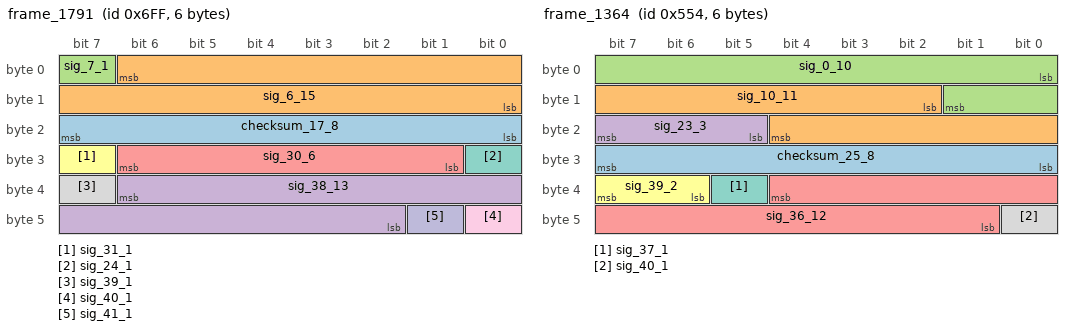
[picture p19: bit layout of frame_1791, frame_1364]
BO_ 1791 frame_1791: 6 Vector__XXX
  SG_ checksum_17_8 : 23|8@0+ (1.0,0.0) [0.0|255.0] "" ECU
  SG_ sig_6_15 : 6|15@0- (1.0000000000000006E-6,0.0) [-0.01638400000000001|0.01638200000000001] "s" ECU
  SG_ sig_7_1 : 7|1@1+ (1.0,0.0) [0.0|1.0] "" ECU
  SG_ sig_38_13 : 38|13@0- (0.1,0.0) [-409.6|409.40000000000003] "W" ECU
  SG_ sig_30_6 : 30|6@0+ (1.0000000000000006E-6,-3.1622776601683795E-5) [-3.1622776601683795E-5|3.0377223398316248E-5] "s" ECU
  SG_ sig_31_1 : 31|1@0+ (1.0,0.0) [0.0|1.0] "" ECU
  SG_ sig_24_1 : 24|1@1+ (1.0,0.0) [0.0|1.0] "" ECU
  SG_ sig_39_1 : 39|1@0+ (1.0,0.0) [0.0|1.0] "" ECU
  SG_ sig_40_1 : 40|1@1+ (1.0,0.0) [0.0|1.0] "" ECU
  SG_ sig_41_1 : 41|1@0+ (1.0,0.0) [0.0|1.0] "" ECU

BO_ 1364 frame_1364: 6 Vector__XXX
  SG_ checksum_25_8 : 24|8@1+ (1.0,0.0) [0.0|255.0] "" ECU
  SG_ sig_10_11 : 10|11@1+ (1.0,0.0) [0.0|2046.0] "" ECU
  SG_ sig_0_10 : 0|10@1- (1.0000000000000007E-7,3.1622776601683795E-5) [-1.9577223398316243E-5|8.262277660168384E-5] "s" ECU
  SG_ sig_23_3 : 23|3@0- (1.0,0.0) [-4.0|2.0] "" ECU
  SG_ sig_36_12 : 36|12@0+ (0.0010000000000000002,-3.1622776601683795) [-3.1622776601683795|0.9317223398316217] "A" ECU
  SG_ sig_39_2 : 39|2@0+ (1.0,0.0) [0.0|3.0] "" ECU
  SG_ sig_37_1 : 37|1@0+ (1.0,0.0) [0.0|1.0] "" ECU
  SG_ sig_40_1 : 40|1@0+ (1.0,0.0) [0.0|1.0] "" ECU

BO_ 677 frame_677: 4 ECU
  SG_ checksum_9_8 : 15|8@0+ (1.0,0.0) [0.0|255.0] "" Vector__XXX
  SG_ sig_6_7 : 6|7@0- (1.0,0.0) [-64.0|62.0] "" Vector__XXX
  SG_ sig_7_1 : 7|1@0+ (1.0,0.0) [0.0|1.0] "" Vector__XXX
  SG_ sig_23_8 : 23|8@0- (0.010000000000000002,-0.31622776601683794) [-1.5962277660168382|0.9437722339831622] "km/h" Vector__XXX
  SG_ sig_25_7 : 25|7@1+ (100.0,0.0) [0.0|12600.0] "kWh" Vector__XXX
  SG_ sig_24_1 : 24|1@0+ (1.0,0.0) [0.0|1.0] "" Vector__XXX

CM_ BO_ 324 "Randomly defined CAN frame";
CM_ SG_ 324 checksum_33_8 "8 Bit checksum for protection of frame contents";
CM_ BO_ 1232 "Randomly defined CAN frame";
CM_ SG_ 1232 checksum_1_8 "8 Bit checksum for protection of frame contents";
CM_ BO_ 161 "Randomly defined CAN frame";
CM_ SG_ 161 checksum_1_8 "8 Bit checksum for protection of frame contents";
CM_ BO_ 1037 "Randomly defined CAN frame";
CM_ SG_ 1037 checksum_25_8 "8 Bit checksum for protection of frame contents";
CM_ BO_ 1129 "Randomly defined CAN frame";
CM_ SG_ 1129 checksum_49_8 "8 Bit checksum for protection of frame contents";
CM_ BO_ 1231 "Randomly defined CAN frame";
CM_ SG_ 1231 checksum_33_8 "8 Bit checksum for protection of frame contents";
CM_ BO_ 892 "Randomly defined CAN frame";
CM_ SG_ 892 checksum_41_8 "8 Bit checksum for protection of frame contents";
CM_ BO_ 612 "Randomly defined CAN frame";
CM_ SG_ 612 checksum_1_8 "8 Bit checksum for protection of frame contents";
CM_ BO_ 1982 "Randomly defined CAN frame";
CM_ SG_ 1982 checksum_1_8 "8 Bit checksum for protection of frame contents";
CM_ BO_ 225 "Randomly defined CAN frame";
CM_ SG_ 225 checksum_33_8 "8 Bit checksum for protection of frame contents";
CM_ BO_ 5 "Randomly defined CAN frame";
CM_ SG_ 5 checksum_17_8 "8 Bit checksum for protection of frame contents";
CM_ BO_ 232 "Randomly defined CAN frame";
CM_ SG_ 232 checksum_25_8 "8 Bit checksum for protection of frame contents";
CM_ BO_ 591 "Randomly defined CAN frame";
CM_ SG_ 591 checksum_41_8 "8 Bit checksum for protection of frame contents";
CM_ BO_ 91 "Randomly defined CAN frame";
CM_ SG_ 91 checksum_9_8 "8 Bit checksum for protection of frame contents";
CM_ BO_ 316 "Randomly defined CAN frame";
CM_ SG_ 316 checksum_25_8 "8 Bit checksum for protection of frame contents";
CM_ BO_ 1841 "Randomly defined CAN frame";
CM_ SG_ 1841 checksum_25_8 "8 Bit checksum for protection of frame contents";
CM_ BO_ 1103 "Randomly defined CAN frame";
CM_ SG_ 1103 checksum_1_8 "8 Bit checksum for protection of frame contents";
CM_ BO_ 109 "Randomly defined CAN frame";
CM_ SG_ 109 checksum_33_8 "8 Bit checksum for protection of frame contents";
CM_ BO_ 1999 "Randomly defined CAN frame";
CM_ SG_ 1999 checksum_25_8 "8 Bit checksum for protection of frame contents";
CM_ BO_ 1477 "Randomly defined CAN frame";
CM_ SG_ 1477 checksum_25_8 "8 Bit checksum for protection of frame contents";
CM_ BO_ 956 "Randomly defined CAN frame";
CM_ SG_ 956 checksum_17_8 "8 Bit checksum for protection of frame contents";
CM_ BO_ 1604 "Randomly defined CAN frame";
CM_ SG_ 1604 checksum_9_8 "8 Bit checksum for protection of frame contents";
CM_ BO_ 36 "Randomly defined CAN frame";
CM_ SG_ 36 checksum_9_8 "8 Bit checksum for protection of frame contents";
CM_ BO_ 1847 "Randomly defined CAN frame";
CM_ SG_ 1847 checksum_1_8 "8 Bit checksum for protection of frame contents";
CM_ BO_ 267 "Randomly defined CAN frame";
CM_ SG_ 267 checksum_33_8 "8 Bit checksum for protection of frame contents";
CM_ BO_ 1407 "Randomly defined CAN frame";
CM_ SG_ 1407 checksum_33_8 "8 Bit checksum for protection of frame contents";
CM_ BO_ 1915 "Randomly defined CAN frame";
CM_ SG_ 1915 checksum_41_8 "8 Bit checksum for protection of frame contents";
CM_ BO_ 2007 "Randomly defined CAN frame";
CM_ SG_ 2007 checksum_17_8 "8 Bit checksum for protection of frame contents";
CM_ BO_ 1194 "Randomly defined CAN frame";
CM_ SG_ 1194 checksum_9_8 "8 Bit checksum for protection of frame contents";
CM_ BO_ 446 "Randomly defined CAN frame";
CM_ SG_ 446 checksum_41_8 "8 Bit checksum for protection of frame contents";
CM_ BO_ 1060 "Randomly defined CAN frame";
CM_ SG_ 1060 checksum_9_8 "8 Bit checksum for protection of frame contents";
CM_ BO_ 2001 "Randomly defined CAN frame";
CM_ SG_ 2001 checksum_41_8 "8 Bit checksum for protection of frame contents";
CM_ BO_ 80 "Randomly defined CAN frame";
CM_ SG_ 80 checksum_1_8 "8 Bit checksum for protection of frame contents";
CM_ BO_ 0 "Randomly defined CAN frame";
CM_ SG_ 0 checksum_1_8 "8 Bit checksum for protection of frame contents";
CM_ BO_ 1702 "Randomly defined CAN frame";
CM_ SG_ 1702 checksum_41_8 "8 Bit checksum for protection of frame contents";
CM_ BO_ 1494 "Randomly defined CAN frame";
CM_ SG_ 1494 checksum_17_8 "8 Bit checksum for protection of frame contents";
CM_ BO_ 964 "Randomly defined CAN frame";
CM_ SG_ 964 checksum_1_8 "8 Bit checksum for protection of frame contents";
CM_ BO_ 400 "Randomly defined CAN frame";
CM_ SG_ 400 checksum_33_8 "8 Bit checksum for protection of frame contents";
CM_ BO_ 264 "Randomly defined CAN frame";
CM_ SG_ 264 checksum_17_8 "8 Bit checksum for protection of frame contents";
CM_ BO_ 479 "Randomly defined CAN frame";
CM_ SG_ 479 checksum_17_8 "8 Bit checksum for protection of frame contents";
CM_ BO_ 502 "Randomly defined CAN frame";
CM_ SG_ 502 checksum_1_8 "8 Bit checksum for protection of frame contents";
CM_ BO_ 537 "Randomly defined CAN frame";
CM_ SG_ 537 checksum_17_8 "8 Bit checksum for protection of frame contents";
CM_ BO_ 741 "Randomly defined CAN frame";
CM_ SG_ 741 checksum_25_8 "8 Bit checksum for protection of frame contents";
CM_ BO_ 1396 "Randomly defined CAN frame";
CM_ SG_ 1396 checksum_1_8 "8 Bit checksum for protection of frame contents";
CM_ BO_ 207 "Randomly defined CAN frame";
CM_ SG_ 207 checksum_17_8 "8 Bit checksum for protection of frame contents";
CM_ BO_ 419 "Randomly defined CAN frame";
CM_ SG_ 419 checksum_1_8 "8 Bit checksum for protection of frame contents";
CM_ BO_ 1325 "Randomly defined CAN frame";
CM_ SG_ 1325 checksum_25_8 "8 Bit checksum for protection of frame contents";
CM_ BO_ 1996 "Randomly defined CAN frame";
CM_ SG_ 1996 checksum_17_8 "8 Bit checksum for protection of frame contents";
CM_ BO_ 1505 "Randomly defined CAN frame";
CM_ SG_ 1505 checksum_17_8 "8 Bit checksum for protection of frame contents";
CM_ BO_ 393 "Randomly defined CAN frame";
CM_ SG_ 393 checksum_25_8 "8 Bit checksum for protection of frame contents";
CM_ BO_ 703 "Randomly defined CAN frame";
CM_ SG_ 703 checksum_33_8 "8 Bit checksum for protection of frame contents";
CM_ BO_ 48 "Randomly defined CAN frame";
CM_ SG_ 48 checksum_33_8 "8 Bit checksum for protection of frame contents";
CM_ BO_ 26 "Randomly defined CAN frame";
CM_ SG_ 26 checksum_9_8 "8 Bit checksum for protection of frame contents";
CM_ BO_ 515 "Randomly defined CAN frame";
CM_ SG_ 515 checksum_9_8 "8 Bit checksum for protection of frame contents";
CM_ BO_ 1570 "Randomly defined CAN frame";
CM_ SG_ 1570 checksum_33_8 "8 Bit checksum for protection of frame contents";
CM_ BO_ 1791 "Randomly defined CAN frame";
CM_ SG_ 1791 checksum_17_8 "8 Bit checksum for protection of frame contents";
CM_ BO_ 1364 "Randomly defined CAN frame";
CM_ SG_ 1364 checksum_25_8 "8 Bit checksum for protection of frame contents";
CM_ BO_ 677 "Randomly defined CAN frame";
CM_ SG_ 677 checksum_9_8 "8 Bit checksum for protection of frame contents";
BA_DEF_ "Author" STRING;
BA_DEF_ BO_ "frameSendMode" ENUM  "regular","event","mixed";
BA_DEF_ BO_ "sendPeriod" INT 5 10000;
BA_DEF_ BO_ "crcStartValue" INT 1 255;
BA_DEF_ BO_ "eventMinDistance" INT 5 10000;
BA_DEF_ SG_ "initialValue" FLOAT -1e38 1e38;
BA_DEF_DEF_ "Author" "http://sourceforge.net/projects/comframe/";
BA_DEF_DEF_ "frameSendMode" "regular";
BA_DEF_DEF_ "sendPeriod" 10;
BA_DEF_DEF_ "crcStartValue" 1;
BA_DEF_DEF_ "eventMinDistance" 10;
BA_DEF_DEF_ "initialValue" 0.0;
BA_ "frameSendMode" BO_ 324 2;
BA_ "sendPeriod" BO_ 324 1000;
BA_ "eventMinDistance" BO_ 324 1000;
BA_ "crcStartValue" BO_ 324 40;
BA_ "initialValue" SG_ 324 sig_10_14 8.189277660168384E-6;
BA_ "initialValue" SG_ 324 sig_6_10 -287.0;
BA_ "initialValue" SG_ 324 sig_7_1 1.0;
BA_ "initialValue" SG_ 324 sig_12_2 3.0;
BA_ "initialValue" SG_ 324 sig_26_3 5.0;
BA_ "initialValue" SG_ 324 sig_24_2 2.0;
BA_ "initialValue" SG_ 324 sig_46_6 5.700000000000003E-5;
BA_ "sendPeriod" BO_ 1232 25;
BA_ "crcStartValue" BO_ 1232 14;
BA_ "initialValue" SG_ 1232 sig_39_12 -5.702776601683772E-6;
BA_ "initialValue" SG_ 1232 sig_15_10 10.412277660168382;
BA_ "initialValue" SG_ 1232 sig_9_6 -0.00406227766016838;
BA_ "initialValue" SG_ 1232 sig_8_1 1.0;
BA_ "initialValue" SG_ 1232 sig_25_6 18000.0;
BA_ "initialValue" SG_ 1232 sig_31_5 -16622.776601683792;
BA_ "initialValue" SG_ 1232 sig_51_10 0.2862277660168379;
BA_ "initialValue" SG_ 1232 sig_61_3 4.0;
BA_ "sendPeriod" BO_ 161 1000;
BA_ "crcStartValue" BO_ 161 26;
BA_ "initialValue" SG_ 161 sig_15_12 -20.36277660168379;
BA_ "initialValue" SG_ 161 sig_33_6 6.1000000000000005;
BA_ "initialValue" SG_ 161 sig_16_1 1.0;
BA_ "initialValue" SG_ 161 sig_29_12 -1538.0;
BA_ "initialValue" SG_ 161 sig_30_2 2.0;
BA_ "initialValue" SG_ 161 sig_43_11 1.2610000000000011E-5;
BA_ "sendPeriod" BO_ 1037 10000;
BA_ "crcStartValue" BO_ 1037 211;
BA_ "initialValue" SG_ 1037 sig_12_1 1.0;
BA_ "initialValue" SG_ 1037 sig_6_10 -496.0;
BA_ "initialValue" SG_ 1037 sig_11_9 0.1762277660168379;
BA_ "initialValue" SG_ 1037 sig_39_6 -21.0;
BA_ "sendPeriod" BO_ 1129 20;
BA_ "crcStartValue" BO_ 1129 229;
BA_ "initialValue" SG_ 1129 sig_2_14 7.029000000000006E-6;
BA_ "initialValue" SG_ 1129 sig_25_13 7671.0;
BA_ "initialValue" SG_ 1129 sig_17_3 5.0;
BA_ "initialValue" SG_ 1129 sig_16_7 60622.77660168379;
BA_ "initialValue" SG_ 1129 sig_44_5 7.000000000000003E-4;
BA_ "sendPeriod" BO_ 1231 50;
BA_ "crcStartValue" BO_ 1231 193;
BA_ "initialValue" SG_ 1231 sig_22_10 3.1772233983162307E-6;
BA_ "initialValue" SG_ 1231 sig_1_7 14262.27766016838;
BA_ "initialValue" SG_ 1231 sig_0_1 1.0;
BA_ "initialValue" SG_ 1231 sig_14_3 -1.0;
BA_ "sendPeriod" BO_ 892 5;
BA_ "crcStartValue" BO_ 892 79;
BA_ "initialValue" SG_ 892 sig_0_11 45.57722339831621;
BA_ "initialValue" SG_ 892 sig_11_12 0.10780000000000005;
BA_ "initialValue" SG_ 892 sig_23_17 879.6223398316206;
BA_ "initialValue" SG_ 892 sig_48_7 5.862277660168381E-5;
BA_ "initialValue" SG_ 892 sig_55_1 1.0;
BA_ "sendPeriod" BO_ 612 20;
BA_ "crcStartValue" BO_ 612 251;
BA_ "initialValue" SG_ 612 sig_16_16 1.6892776601683788;
BA_ "initialValue" SG_ 612 sig_15_9 -7.322776601683777E-6;
BA_ "initialValue" SG_ 612 sig_22_6 -0.007622776601683784;
BA_ "frameSendMode" BO_ 1982 2;
BA_ "sendPeriod" BO_ 1982 500;
BA_ "eventMinDistance" BO_ 1982 500;
BA_ "crcStartValue" BO_ 1982 240;
BA_ "initialValue" SG_ 1982 sig_18_20 1.2441797660168389E-5;
BA_ "initialValue" SG_ 1982 sig_12_5 1.7000000000000013E-6;
BA_ "initialValue" SG_ 1982 sig_8_3 4.0;
BA_ "initialValue" SG_ 1982 sig_17_1 1.0;
BA_ "initialValue" SG_ 1982 sig_48_12 7.760000000000006E-5;
BA_ "initialValue" SG_ 1982 sig_60_4 -21622.776601683792;
BA_ "frameSendMode" BO_ 225 2;
BA_ "sendPeriod" BO_ 225 100;
BA_ "eventMinDistance" BO_ 225 100;
BA_ "crcStartValue" BO_ 225 146;
BA_ "initialValue" SG_ 225 sig_3_15 -8478.0;
BA_ "initialValue" SG_ 225 sig_7_3 1.0;
BA_ "initialValue" SG_ 225 sig_16_5 4.4622776601683806E-5;
BA_ "initialValue" SG_ 225 sig_30_7 -19.0;
BA_ "initialValue" SG_ 225 sig_42_6 -0.46227766016837935;
BA_ "initialValue" SG_ 225 sig_40_2 1.0;
BA_ "sendPeriod" BO_ 5 10000;
BA_ "crcStartValue" BO_ 5 114;
BA_ "initialValue" SG_ 5 sig_0_13 2.6710000000000025E-6;
BA_ "initialValue" SG_ 5 sig_31_8 122.0;
BA_ "frameSendMode" BO_ 232 2;
BA_ "sendPeriod" BO_ 232 10000;
BA_ "eventMinDistance" BO_ 232 100;
BA_ "crcStartValue" BO_ 232 152;
BA_ "initialValue" SG_ 232 sig_7_12 3.8000000000000033E-7;
BA_ "initialValue" SG_ 232 sig_0_5 1.2000000000000007E-5;
BA_ "initialValue" SG_ 232 sig_5_2 3.0;
BA_ "initialValue" SG_ 232 sig_23_5 -3.0;
BA_ "initialValue" SG_ 232 sig_43_14 -0.004587223398316229;
BA_ "initialValue" SG_ 232 sig_32_9 7300.0;
BA_ "initialValue" SG_ 232 sig_57_7 129622.77660168378;
BA_ "sendPeriod" BO_ 591 50;
BA_ "crcStartValue" BO_ 591 234;
BA_ "initialValue" SG_ 591 sig_27_7 0.1336227766016838;
BA_ "initialValue" SG_ 591 sig_9_8 11262.27766016838;
BA_ "initialValue" SG_ 591 sig_7_12 4.750277660168381E-6;
BA_ "initialValue" SG_ 591 sig_17_6 133.77223398316204;
BA_ "initialValue" SG_ 591 sig_32_5 9000.0;
BA_ "initialValue" SG_ 591 sig_53_6 22.0;
BA_ "initialValue" SG_ 591 sig_55_2 1.0;
BA_ "sendPeriod" BO_ 91 500;
BA_ "crcStartValue" BO_ 91 193;
BA_ "initialValue" SG_ 91 sig_0_4 8.377223398316224E-5;
BA_ "initialValue" SG_ 91 sig_4_4 -4.0;
BA_ "initialValue" SG_ 91 sig_17_21 -2.018277660168378E-6;
BA_ "initialValue" SG_ 91 sig_19_3 -3.0;
BA_ "initialValue" SG_ 91 sig_18_1 1.0;
BA_ "initialValue" SG_ 91 sig_41_3 5.0;
BA_ "initialValue" SG_ 91 sig_40_1 1.0;
BA_ "initialValue" SG_ 91 sig_44_1 1.0;
BA_ "sendPeriod" BO_ 316 20;
BA_ "crcStartValue" BO_ 316 23;
BA_ "initialValue" SG_ 316 sig_6_15 2.419800000000002E-4;
BA_ "initialValue" SG_ 316 sig_22_7 67622.77660168378;
BA_ "initialValue" SG_ 316 sig_39_15 5.240677660168381E-5;
BA_ "initialValue" SG_ 316 sig_40_1 1.0;
BA_ "sendPeriod" BO_ 1841 100;
BA_ "crcStartValue" BO_ 1841 141;
BA_ "initialValue" SG_ 1841 sig_1_13 8.057223398316238E-6;
BA_ "initialValue" SG_ 1841 sig_0_3 1.0;
BA_ "initialValue" SG_ 1841 sig_20_5 -7.0;
BA_ "initialValue" SG_ 1841 sig_21_3 2.0;
BA_ "initialValue" SG_ 1841 sig_42_15 2474.0;
BA_ "initialValue" SG_ 1841 sig_34_8 75.0;
BA_ "initialValue" SG_ 1841 sig_35_4 -71622.77660168378;
BA_ "initialValue" SG_ 1841 sig_56_4 816.2277660168379;
BA_ "sendPeriod" BO_ 1103 500;
BA_ "crcStartValue" BO_ 1103 77;
BA_ "initialValue" SG_ 1103 sig_27_23 -4.2885566016837524E-7;
BA_ "initialValue" SG_ 1103 sig_20_7 -0.02037722339831622;
BA_ "initialValue" SG_ 1103 sig_12_8 0.0018737722339831635;
BA_ "initialValue" SG_ 1103 sig_13_1 1.0;
BA_ "initialValue" SG_ 1103 sig_28_2 2.0;
BA_ "initialValue" SG_ 1103 sig_52_5 -2.5622776601683794;
BA_ "sendPeriod" BO_ 109 10000;
BA_ "crcStartValue" BO_ 109 212;
BA_ "initialValue" SG_ 109 sig_7_16 228.02000000000004;
BA_ "initialValue" SG_ 109 sig_17_5 2.4000000000000016E-6;
BA_ "initialValue" SG_ 109 sig_47_5 -1.3;
BA_ "initialValue" SG_ 109 sig_40_3 2.0;
BA_ "sendPeriod" BO_ 1999 100;
BA_ "crcStartValue" BO_ 1999 205;
BA_ "initialValue" SG_ 1999 sig_2_19 63297.0;
BA_ "initialValue" SG_ 1999 sig_7_5 2.9622776601683794E-5;
BA_ "initialValue" SG_ 1999 sig_44_12 3.798000000000001;
BA_ "initialValue" SG_ 1999 sig_36_5 -5000.0;
BA_ "initialValue" SG_ 1999 sig_38_2 3.0;
BA_ "initialValue" SG_ 1999 sig_40_4 -0.016227766016837897;
BA_ "sendPeriod" BO_ 1477 500;
BA_ "crcStartValue" BO_ 1477 109;
BA_ "initialValue" SG_ 1477 sig_8_9 -21.0;
BA_ "initialValue" SG_ 1477 sig_0_1 1.0;
BA_ "initialValue" SG_ 1477 sig_7_4 0.0013162277660168384;
BA_ "initialValue" SG_ 1477 sig_15_7 0.0736227766016838;
BA_ "initialValue" SG_ 1477 sig_33_15 4350.17766016838;
BA_ "crcStartValue" BO_ 956 55;
BA_ "initialValue" SG_ 956 sig_3_13 0.6447000000000003;
BA_ "initialValue" SG_ 956 sig_27_16 4463.0;
BA_ "initialValue" SG_ 956 sig_28_4 60.0;
BA_ "initialValue" SG_ 956 sig_43_1 1.0;
BA_ "initialValue" SG_ 956 sig_48_7 6.200000000000004E-5;
BA_ "sendPeriod" BO_ 1604 10000;
BA_ "crcStartValue" BO_ 1604 165;
BA_ "initialValue" SG_ 1604 sig_1_7 11.66227766016838;
BA_ "initialValue" SG_ 1604 sig_19_35 275.65498206000024;
BA_ "initialValue" SG_ 1604 sig_16_3 -4.0;
BA_ "sendPeriod" BO_ 36 20;
BA_ "crcStartValue" BO_ 36 70;
BA_ "initialValue" SG_ 36 sig_5_6 346.22776601683796;
BA_ "initialValue" SG_ 36 sig_7_2 3.0;
BA_ "initialValue" SG_ 36 sig_28_13 -1.4360000000000004;
BA_ "initialValue" SG_ 36 sig_23_9 3620.0;
BA_ "initialValue" SG_ 36 sig_45_13 7179.0;
BA_ "initialValue" SG_ 36 sig_47_2 3.0;
BA_ "sendPeriod" BO_ 1847 10000;
BA_ "crcStartValue" BO_ 1847 96;
BA_ "initialValue" SG_ 1847 sig_24_15 25525.0;
BA_ "initialValue" SG_ 1847 sig_8_14 -7059.0;
BA_ "initialValue" SG_ 1847 sig_22_2 -1.0;
BA_ "initialValue" SG_ 1847 sig_40_8 14662.27766016838;
BA_ "sendPeriod" BO_ 267 10000;
BA_ "crcStartValue" BO_ 267 110;
BA_ "initialValue" SG_ 267 sig_17_8 217.0;
BA_ "initialValue" SG_ 267 sig_7_22 -4.3428726601683806E-4;
BA_ "initialValue" SG_ 267 sig_25_2 3.0;
BA_ "initialValue" SG_ 267 sig_50_10 65522.77660168379;
BA_ "initialValue" SG_ 267 sig_47_13 1808.0;
BA_ "sendPeriod" BO_ 1407 100;
BA_ "crcStartValue" BO_ 1407 225;
BA_ "initialValue" SG_ 1407 sig_13_18 60685.0;
BA_ "initialValue" SG_ 1407 sig_0_8 0.0024362277660168394;
BA_ "initialValue" SG_ 1407 sig_14_1 1.0;
BA_ "initialValue" SG_ 1407 sig_27_3 -4.0;
BA_ "initialValue" SG_ 1407 sig_54_13 6835.0;
BA_ "initialValue" SG_ 1407 sig_47_9 39.0;
BA_ "sendPeriod" BO_ 1915 25;
BA_ "crcStartValue" BO_ 1915 158;
BA_ "initialValue" SG_ 1915 sig_10_27 0.038040937398316266;
BA_ "initialValue" SG_ 1915 sig_4_6 5.0;
BA_ "initialValue" SG_ 1915 sig_0_4 4.0000000000000024E-5;
BA_ "initialValue" SG_ 1915 sig_39_3 6.0;
BA_ "initialValue" SG_ 1915 sig_56_7 -57.0;
BA_ "initialValue" SG_ 1915 sig_52_5 0.8;
BA_ "initialValue" SG_ 1915 sig_53_2 -2.0;
BA_ "initialValue" SG_ 1915 sig_55_1 1.0;
BA_ "initialValue" SG_ 1915 sig_63_1 1.0;
BA_ "frameSendMode" BO_ 2007 2;
BA_ "sendPeriod" BO_ 2007 100;
BA_ "eventMinDistance" BO_ 2007 100;
BA_ "crcStartValue" BO_ 2007 160;
BA_ "initialValue" SG_ 2007 sig_4_12 3.447000000000003E-6;
BA_ "initialValue" SG_ 2007 sig_0_4 0.0010837722339831627;
BA_ "initialValue" SG_ 2007 sig_26_4 0.015162277660168384;
BA_ "initialValue" SG_ 2007 sig_24_2 2.0;
BA_ "sendPeriod" BO_ 1194 10000;
BA_ "crcStartValue" BO_ 1194 230;
BA_ "initialValue" SG_ 1194 sig_6_7 29.0;
BA_ "initialValue" SG_ 1194 sig_55_9 0.1457722339831622;
BA_ "initialValue" SG_ 1194 sig_35_2 2.0;
BA_ "initialValue" SG_ 1194 sig_23_19 53558.27660168379;
BA_ "initialValue" SG_ 1194 sig_41_6 49.0;
BA_ "initialValue" SG_ 1194 sig_56_7 47.0;
BA_ "sendPeriod" BO_ 446 20;
BA_ "crcStartValue" BO_ 446 149;
BA_ "initialValue" SG_ 446 sig_8_21 0.6826600000000004;
BA_ "initialValue" SG_ 446 sig_7_14 7329.0;
BA_ "initialValue" SG_ 446 sig_32_4 -0.011162277660168382;
BA_ "initialValue" SG_ 446 sig_54_14 3192.0;
BA_ "frameSendMode" BO_ 1060 2;
BA_ "sendPeriod" BO_ 1060 1000;
BA_ "eventMinDistance" BO_ 1060 500;
BA_ "crcStartValue" BO_ 1060 41;
BA_ "initialValue" SG_ 1060 sig_1_7 6.262277660168381E-4;
BA_ "initialValue" SG_ 1060 sig_16_7 52.0;
BA_ "sendPeriod" BO_ 2001 20;
BA_ "crcStartValue" BO_ 2001 222;
BA_ "initialValue" SG_ 2001 sig_14_12 4.07627766016838E-5;
BA_ "initialValue" SG_ 2001 sig_2_5 2900.0;
BA_ "initialValue" SG_ 2001 sig_1_3 1.0;
BA_ "initialValue" SG_ 2001 sig_31_15 2231.0;
BA_ "crcStartValue" BO_ 80 29;
BA_ "initialValue" SG_ 80 sig_22_27 5.2451694000000035;
BA_ "initialValue" SG_ 80 sig_15_8 1.7137722339831623;
BA_ "crcStartValue" BO_ 0 87;
BA_ "initialValue" SG_ 0 sig_11_23 7.703797660168386E-6;
BA_ "sendPeriod" BO_ 1702 10000;
BA_ "crcStartValue" BO_ 1702 52;
BA_ "initialValue" SG_ 1702 sig_14_9 204.0;
BA_ "initialValue" SG_ 1702 sig_5_7 44.0;
BA_ "initialValue" SG_ 1702 sig_7_2 -1.0;
BA_ "initialValue" SG_ 1702 sig_26_8 -0.01662277660168379;
BA_ "initialValue" SG_ 1702 sig_21_11 -1007.0;
BA_ "initialValue" SG_ 1702 sig_34_3 5.0;
BA_ "initialValue" SG_ 1702 sig_53_14 0.0013008277660168388;
BA_ "initialValue" SG_ 1702 sig_54_1 1.0;
BA_ "crcStartValue" BO_ 1494 125;
BA_ "initialValue" SG_ 1494 sig_5_11 1728.0;
BA_ "initialValue" SG_ 1494 sig_1_4 91622.77660168378;
BA_ "initialValue" SG_ 1494 sig_31_3 2.0;
BA_ "crcStartValue" BO_ 964 197;
BA_ "initialValue" SG_ 964 sig_10_3 5.0;
BA_ "initialValue" SG_ 964 sig_39_16 11350.0;
BA_ "initialValue" SG_ 964 sig_20_10 0.03027722339831624;
BA_ "initialValue" SG_ 964 sig_19_4 2.0;
BA_ "initialValue" SG_ 964 sig_30_2 -2.0;
BA_ "frameSendMode" BO_ 400 1;
BA_ "eventMinDistance" BO_ 400 50;
BA_ "crcStartValue" BO_ 400 165;
BA_ "initialValue" SG_ 400 sig_1_18 9592.0;
BA_ "initialValue" SG_ 400 sig_20_11 -9.880000000000006E-4;
BA_ "initialValue" SG_ 400 sig_19_1 1.0;
BA_ "initialValue" SG_ 400 sig_46_5 -0.003000000000000001;
BA_ "frameSendMode" BO_ 264 2;
BA_ "sendPeriod" BO_ 264 50;
BA_ "eventMinDistance" BO_ 264 50;
BA_ "crcStartValue" BO_ 264 90;
BA_ "initialValue" SG_ 264 sig_7_14 15.507223398316217;
BA_ "initialValue" SG_ 264 sig_9_2 2.0;
BA_ "initialValue" SG_ 264 sig_30_6 21.0;
BA_ "sendPeriod" BO_ 479 10000;
BA_ "crcStartValue" BO_ 479 100;
BA_ "initialValue" SG_ 479 sig_0_16 9557.07766016838;
BA_ "initialValue" SG_ 479 sig_30_12 42472.77660168379;
BA_ "sendPeriod" BO_ 502 25;
BA_ "crcStartValue" BO_ 502 160;
BA_ "initialValue" SG_ 502 sig_12_14 12207.0;
BA_ "initialValue" SG_ 502 sig_24_5 3162.2776601683795;
BA_ "initialValue" SG_ 502 sig_34_14 4.2700000000000035E-5;
BA_ "initialValue" SG_ 502 sig_39_5 -2.862277660168379E-4;
BA_ "initialValue" SG_ 502 sig_52_5 3.3622776601683797;
BA_ "sendPeriod" BO_ 537 1000;
BA_ "crcStartValue" BO_ 537 84;
BA_ "initialValue" SG_ 537 sig_6_12 -1.976000000000002E-6;
BA_ "initialValue" SG_ 537 sig_7_1 1.0;
BA_ "initialValue" SG_ 537 sig_8_3 5.0;
BA_ "initialValue" SG_ 537 sig_29_10 818.0;
BA_ "initialValue" SG_ 537 sig_28_6 42.0;
BA_ "initialValue" SG_ 537 sig_41_15 -5.252000000000002;
BA_ "initialValue" SG_ 537 sig_40_1 1.0;
BA_ "sendPeriod" BO_ 741 5;
BA_ "crcStartValue" BO_ 741 110;
BA_ "initialValue" SG_ 741 sig_5_13 0.0010687277660168385;
BA_ "initialValue" SG_ 741 sig_2_3 5.0;
BA_ "initialValue" SG_ 741 sig_0_2 -1.0;
BA_ "initialValue" SG_ 741 sig_19_3 2.0;
BA_ "initialValue" SG_ 741 sig_32_14 -3949.0;
BA_ "frameSendMode" BO_ 1396 2;
BA_ "sendPeriod" BO_ 1396 1000;
BA_ "eventMinDistance" BO_ 1396 100;
BA_ "crcStartValue" BO_ 1396 194;
BA_ "initialValue" SG_ 1396 sig_8_8 0.011137722339831627;
BA_ "sendPeriod" BO_ 207 10000;
BA_ "crcStartValue" BO_ 207 196;
BA_ "initialValue" SG_ 207 sig_1_11 106.4227766016838;
BA_ "initialValue" SG_ 207 sig_12_4 0.006000000000000002;
BA_ "initialValue" SG_ 207 sig_32_11 -452.0;
BA_ "initialValue" SG_ 207 sig_26_6 -8.0;
BA_ "initialValue" SG_ 207 sig_24_2 1.0;
BA_ "initialValue" SG_ 207 sig_46_9 227.0;
BA_ "sendPeriod" BO_ 419 10000;
BA_ "crcStartValue" BO_ 419 48;
BA_ "initialValue" SG_ 419 sig_31_23 0.001193593398316234;
BA_ "initialValue" SG_ 419 sig_11_9 8.800000000000008E-7;
BA_ "initialValue" SG_ 419 sig_15_4 2837.7223398316205;
BA_ "initialValue" SG_ 419 sig_17_1 1.0;
BA_ "initialValue" SG_ 419 sig_40_1 1.0;
BA_ "frameSendMode" BO_ 1325 2;
BA_ "sendPeriod" BO_ 1325 1000;
BA_ "eventMinDistance" BO_ 1325 1000;
BA_ "crcStartValue" BO_ 1325 86;
BA_ "initialValue" SG_ 1325 sig_2_16 0.3163200000000002;
BA_ "initialValue" SG_ 1325 sig_18_5 30.0;
BA_ "initialValue" SG_ 1325 sig_23_1 1.0;
BA_ "initialValue" SG_ 1325 sig_35_21 523.7182339831622;
BA_ "initialValue" SG_ 1325 sig_32_3 -4.0;
BA_ "initialValue" SG_ 1325 sig_62_6 -0.0456227766016838;
BA_ "initialValue" SG_ 1325 sig_56_1 1.0;
BA_ "crcStartValue" BO_ 1996 83;
BA_ "initialValue" SG_ 1996 sig_2_10 -325.0;
BA_ "initialValue" SG_ 1996 sig_5_3 2.0;
BA_ "initialValue" SG_ 1996 sig_7_2 1.0;
BA_ "initialValue" SG_ 1996 sig_8_1 1.0;
BA_ "initialValue" SG_ 1996 sig_37_12 959.0;
BA_ "initialValue" SG_ 1996 sig_31_9 -197.0;
BA_ "initialValue" SG_ 1996 sig_50_3 -4.0;
BA_ "initialValue" SG_ 1996 sig_41_6 42.622776601683796;
BA_ "crcStartValue" BO_ 1505 240;
BA_ "initialValue" SG_ 1505 sig_3_13 4.129722339831627E-5;
BA_ "initialValue" SG_ 1505 sig_2_3 3.0;
BA_ "initialValue" SG_ 1505 sig_27_9 78.6227766016838;
BA_ "initialValue" SG_ 1505 sig_24_3 -1.0;
BA_ "initialValue" SG_ 1505 sig_36_12 5.983277660168382E-5;
BA_ "frameSendMode" BO_ 393 2;
BA_ "sendPeriod" BO_ 393 500;
BA_ "eventMinDistance" BO_ 393 100;
BA_ "crcStartValue" BO_ 393 245;
BA_ "initialValue" SG_ 393 sig_9_12 -1761.0;
BA_ "initialValue" SG_ 393 sig_7_8 -0.7377223398316208;
BA_ "initialValue" SG_ 393 sig_8_1 1.0;
BA_ "initialValue" SG_ 393 sig_22_2 1.0;
BA_ "initialValue" SG_ 393 sig_47_1 1.0;
BA_ "frameSendMode" BO_ 703 2;
BA_ "sendPeriod" BO_ 703 10000;
BA_ "eventMinDistance" BO_ 703 1000;
BA_ "crcStartValue" BO_ 703 128;
BA_ "initialValue" SG_ 703 sig_6_8 7.377223398316222E-4;
BA_ "initialValue" SG_ 703 sig_7_1 1.0;
BA_ "initialValue" SG_ 703 sig_9_5 2.4622776601683787E-6;
BA_ "initialValue" SG_ 703 sig_14_1 1.0;
BA_ "initialValue" SG_ 703 sig_29_6 28.0;
BA_ "initialValue" SG_ 703 sig_16_4 9.162277660168383E-6;
BA_ "initialValue" SG_ 703 sig_48_7 0.006700000000000003;
BA_ "initialValue" SG_ 703 sig_47_7 50.0;
BA_ "initialValue" SG_ 703 sig_40_2 1.0;
BA_ "sendPeriod" BO_ 48 20;
BA_ "crcStartValue" BO_ 48 149;
BA_ "initialValue" SG_ 48 sig_7_10 -3000.0;
BA_ "initialValue" SG_ 48 sig_30_7 -3.0;
BA_ "initialValue" SG_ 48 sig_13_12 1697.0;
BA_ "initialValue" SG_ 48 sig_52_13 0.8260277660168382;
BA_ "initialValue" SG_ 48 sig_47_11 90600.0;
BA_ "sendPeriod" BO_ 26 1000;
BA_ "crcStartValue" BO_ 26 11;
BA_ "initialValue" SG_ 26 sig_0_8 1.0000000000000007E-7;
BA_ "initialValue" SG_ 26 sig_31_28 28480.76856016839;
BA_ "initialValue" SG_ 26 sig_17_7 -5.0;
BA_ "sendPeriod" BO_ 515 25;
BA_ "crcStartValue" BO_ 515 48;
BA_ "initialValue" SG_ 515 sig_6_7 93.0;
BA_ "initialValue" SG_ 515 sig_22_14 1.7462277660168393E-5;
BA_ "initialValue" SG_ 515 sig_23_2 2.0;
BA_ "crcStartValue" BO_ 1570 43;
BA_ "initialValue" SG_ 1570 sig_14_16 0.03571776601683779;
BA_ "initialValue" SG_ 1570 sig_0_8 33.0;
BA_ "initialValue" SG_ 1570 sig_8_6 0.496227766016838;
BA_ "initialValue" SG_ 1570 sig_42_14 -0.0016022776601683786;
BA_ "initialValue" SG_ 1570 sig_40_2 -2.0;
BA_ "sendPeriod" BO_ 1791 25;
BA_ "crcStartValue" BO_ 1791 198;
BA_ "initialValue" SG_ 1791 sig_6_15 -0.012638000000000007;
BA_ "initialValue" SG_ 1791 sig_38_13 133.4;
BA_ "initialValue" SG_ 1791 sig_30_6 7.377223398316231E-6;
BA_ "initialValue" SG_ 1791 sig_31_1 1.0;
BA_ "initialValue" SG_ 1791 sig_24_1 1.0;
BA_ "initialValue" SG_ 1791 sig_39_1 1.0;
BA_ "sendPeriod" BO_ 1364 500;
BA_ "crcStartValue" BO_ 1364 15;
BA_ "initialValue" SG_ 1364 sig_10_11 1060.0;
BA_ "initialValue" SG_ 1364 sig_0_10 -1.4577223398316237E-5;
BA_ "initialValue" SG_ 1364 sig_23_3 2.0;
BA_ "initialValue" SG_ 1364 sig_36_12 -0.8302776601683788;
BA_ "initialValue" SG_ 1364 sig_39_2 2.0;
BA_ "initialValue" SG_ 1364 sig_37_1 1.0;
BA_ "sendPeriod" BO_ 677 50;
BA_ "crcStartValue" BO_ 677 219;
BA_ "initialValue" SG_ 677 sig_6_7 -32.0;
BA_ "initialValue" SG_ 677 sig_23_8 -0.826227766016838;
BA_ "initialValue" SG_ 677 sig_25_7 4300.0;
BA_ "initialValue" SG_ 677 sig_24_1 1.0;
